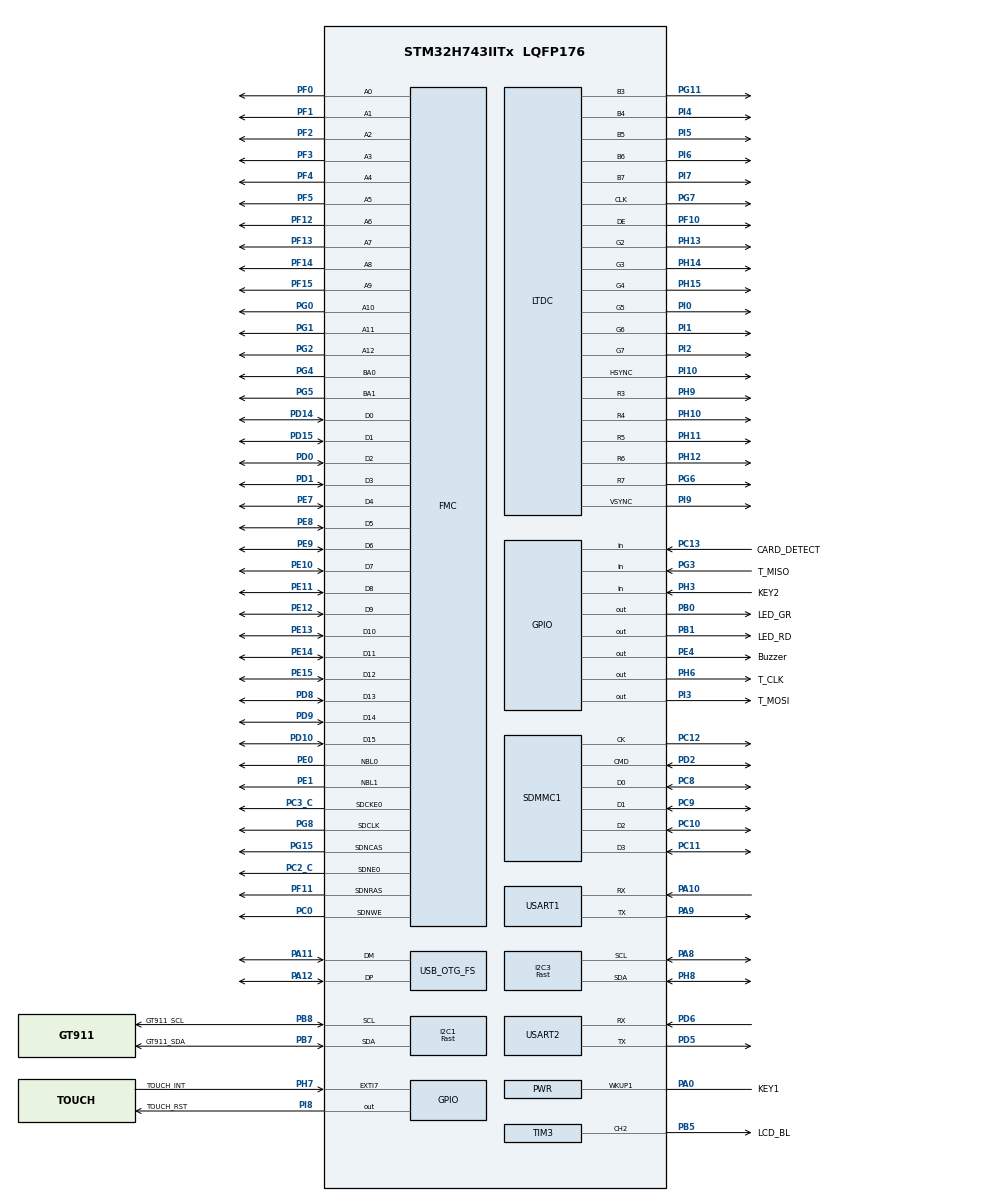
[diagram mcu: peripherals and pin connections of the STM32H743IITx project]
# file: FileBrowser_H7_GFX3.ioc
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ADC3.Channel-0\#ChannelRegularConversion=ADC_CHANNEL_VBAT
ADC3.Channel-1\#ChannelRegularConversion=ADC_CHANNEL_TEMPSENSOR
ADC3.Channel-2\#ChannelRegularConversion=ADC_CHANNEL_VREFINT
ADC3.ClockPrescaler=ADC_CLOCK_ASYNC_DIV6
ADC3.ClockPrescalerADC3=ADC_CLOCK_ASYNC_DIV6
ADC3.ContinuousConvMode=DISABLE
ADC3.ConversionDataManagement=ADC_CONVERSIONDATA_DMA_CIRCULAR
ADC3.EOCSelection=ADC_EOC_SINGLE_CONV
ADC3.ExternalTrigConv=ADC_EXTERNALTRIG_T8_TRGO
ADC3.ExternalTrigConvEdge=ADC_EXTERNALTRIGCONVEDGE_RISING
ADC3.LowPowerAutoWait=DISABLE
ADC3.NbrOfConversion=3
ADC3.NbrOfConversionFlag=1
ADC3.OffsetNumber-0\#ChannelRegularConversion=ADC_OFFSET_NONE
ADC3.OffsetNumber-1\#ChannelRegularConversion=ADC_OFFSET_NONE
ADC3.OffsetNumber-2\#ChannelRegularConversion=ADC_OFFSET_NONE
ADC3.OffsetSignedSaturation-0\#ChannelRegularConversion=DISABLE
ADC3.OffsetSignedSaturation-1\#ChannelRegularConversion=DISABLE
ADC3.OffsetSignedSaturation-2\#ChannelRegularConversion=DISABLE
ADC3.Overrun=ADC_OVR_DATA_PRESERVED
ADC3.OversamplingMode=ENABLE
ADC3.Rank-0\#ChannelRegularConversion=1
ADC3.Rank-1\#ChannelRegularConversion=2
ADC3.Rank-2\#ChannelRegularConversion=3
ADC3.Ratio=1024
ADC3.RightBitShift=ADC_RIGHTBITSHIFT_10
ADC3.SamplingTime-0\#ChannelRegularConversion=ADC_SAMPLETIME_64CYCLES_5
ADC3.SamplingTime-1\#ChannelRegularConversion=ADC_SAMPLETIME_64CYCLES_5
ADC3.SamplingTime-2\#ChannelRegularConversion=ADC_SAMPLETIME_64CYCLES_5
CORTEX_M7.AccessPermission-Cortex_Memory_Protection_Unit_Region0_Settings=MPU_REGION_FULL_ACCESS
CORTEX_M7.AccessPermission-Cortex_Memory_Protection_Unit_Region2_Settings=MPU_REGION_FULL_ACCESS
CORTEX_M7.AccessPermission-Cortex_Memory_Protection_Unit_Region3_Settings=MPU_REGION_FULL_ACCESS
CORTEX_M7.AccessPermission-Cortex_Memory_Protection_Unit_Region4_Settings=MPU_REGION_FULL_ACCESS
CORTEX_M7.AccessPermission-Cortex_Memory_Protection_Unit_Region5_Settings=MPU_REGION_FULL_ACCESS
CORTEX_M7.AccessPermission-Cortex_Memory_Protection_Unit_Region6_Settings=MPU_REGION_FULL_ACCESS
CORTEX_M7.AccessPermission-Cortex_Memory_Protection_Unit_Region7_Settings=MPU_REGION_FULL_ACCESS
CORTEX_M7.BaseAddress-Cortex_Memory_Protection_Unit_Region0_Settings=0x24000000
CORTEX_M7.BaseAddress-Cortex_Memory_Protection_Unit_Region1_Settings=0xC0000000
CORTEX_M7.BaseAddress-Cortex_Memory_Protection_Unit_Region2_Settings=0xC0000000
CORTEX_M7.BaseAddress-Cortex_Memory_Protection_Unit_Region3_Settings=0x90000000
CORTEX_M7.BaseAddress-Cortex_Memory_Protection_Unit_Region4_Settings=0x90000000
CORTEX_M7.BaseAddress-Cortex_Memory_Protection_Unit_Region5_Settings=0x90000000
CORTEX_M7.BaseAddress-Cortex_Memory_Protection_Unit_Region6_Settings=0x30000000
CORTEX_M7.BaseAddress-Cortex_Memory_Protection_Unit_Region7_Settings=0x38000000
CORTEX_M7.CPU_DCache=Enabled
CORTEX_M7.CPU_ICache=Enabled
CORTEX_M7.DisableExec-Cortex_Memory_Protection_Unit_Region0_Settings=MPU_INSTRUCTION_ACCESS_DISABLE
CORTEX_M7.DisableExec-Cortex_Memory_Protection_Unit_Region1_Settings=MPU_INSTRUCTION_ACCESS_DISABLE
CORTEX_M7.DisableExec-Cortex_Memory_Protection_Unit_Region2_Settings=MPU_INSTRUCTION_ACCESS_DISABLE
CORTEX_M7.DisableExec-Cortex_Memory_Protection_Unit_Region3_Settings=MPU_INSTRUCTION_ACCESS_DISABLE
CORTEX_M7.DisableExec-Cortex_Memory_Protection_Unit_Region4_Settings=MPU_INSTRUCTION_ACCESS_ENABLE
CORTEX_M7.DisableExec-Cortex_Memory_Protection_Unit_Region6_Settings=MPU_INSTRUCTION_ACCESS_DISABLE
CORTEX_M7.DisableExec-Cortex_Memory_Protection_Unit_Region7_Settings=MPU_INSTRUCTION_ACCESS_DISABLE
CORTEX_M7.Enable-Cortex_Memory_Protection_Unit_Region0_Settings=MPU_REGION_ENABLE
CORTEX_M7.Enable-Cortex_Memory_Protection_Unit_Region1_Settings=MPU_REGION_ENABLE
CORTEX_M7.Enable-Cortex_Memory_Protection_Unit_Region2_Settings=MPU_REGION_ENABLE
CORTEX_M7.Enable-Cortex_Memory_Protection_Unit_Region3_Settings=MPU_REGION_ENABLE
CORTEX_M7.Enable-Cortex_Memory_Protection_Unit_Region4_Settings=MPU_REGION_ENABLE
CORTEX_M7.Enable-Cortex_Memory_Protection_Unit_Region5_Settings=MPU_REGION_ENABLE
CORTEX_M7.Enable-Cortex_Memory_Protection_Unit_Region6_Settings=MPU_REGION_ENABLE
CORTEX_M7.Enable-Cortex_Memory_Protection_Unit_Region7_Settings=MPU_REGION_ENABLE
CORTEX_M7.Enable-Cortex_Memory_Protection_Unit_Region8_Settings=__NULL
CORTEX_M7.IsBufferable-Cortex_Memory_Protection_Unit_Region0_Settings=MPU_ACCESS_BUFFERABLE
CORTEX_M7.IsBufferable-Cortex_Memory_Protection_Unit_Region2_Settings=MPU_ACCESS_BUFFERABLE
CORTEX_M7.IsBufferable-Cortex_Memory_Protection_Unit_Region3_Settings=MPU_ACCESS_BUFFERABLE
CORTEX_M7.IsBufferable-Cortex_Memory_Protection_Unit_Region4_Settings=MPU_ACCESS_BUFFERABLE
CORTEX_M7.IsBufferable-Cortex_Memory_Protection_Unit_Region5_Settings=MPU_ACCESS_BUFFERABLE
CORTEX_M7.IsCacheable-Cortex_Memory_Protection_Unit_Region0_Settings=MPU_ACCESS_CACHEABLE
CORTEX_M7.IsCacheable-Cortex_Memory_Protection_Unit_Region2_Settings=MPU_ACCESS_CACHEABLE
CORTEX_M7.IsCacheable-Cortex_Memory_Protection_Unit_Region3_Settings=MPU_ACCESS_CACHEABLE
CORTEX_M7.IsCacheable-Cortex_Memory_Protection_Unit_Region4_Settings=MPU_ACCESS_CACHEABLE
CORTEX_M7.IsCacheable-Cortex_Memory_Protection_Unit_Region5_Settings=MPU_ACCESS_CACHEABLE
CORTEX_M7.MPU_Control=MPU_PRIVILEGED_DEFAULT
CORTEX_M7.Size-Cortex_Memory_Protection_Unit_Region0_Settings=MPU_REGION_SIZE_512KB
CORTEX_M7.Size-Cortex_Memory_Protection_Unit_Region1_Settings=MPU_REGION_SIZE_512MB
CORTEX_M7.Size-Cortex_Memory_Protection_Unit_Region2_Settings=MPU_REGION_SIZE_32MB
CORTEX_M7.Size-Cortex_Memory_Protection_Unit_Region3_Settings=MPU_REGION_SIZE_512MB
CORTEX_M7.Size-Cortex_Memory_Protection_Unit_Region4_Settings=MPU_REGION_SIZE_32MB
CORTEX_M7.Size-Cortex_Memory_Protection_Unit_Region5_Settings=MPU_REGION_SIZE_1MB
CORTEX_M7.Size-Cortex_Memory_Protection_Unit_Region6_Settings=MPU_REGION_SIZE_64KB
CORTEX_M7.Size-Cortex_Memory_Protection_Unit_Region7_Settings=MPU_REGION_SIZE_32KB
CORTEX_M7.default_mode_Activation=0
CRC.OutputDataInversionMode=CRC_OUTPUTDATA_INVERSION_DISABLE
DMA2D.ColorMode=DMA2D_OUTPUT_RGB565
DMA2D.Mode=DMA2D_M2M
Dma.ADC3.0.Direction=DMA_PERIPH_TO_MEMORY
Dma.ADC3.0.EventEnable=DISABLE
Dma.ADC3.0.FIFOMode=DMA_FIFOMODE_DISABLE
Dma.ADC3.0.Instance=DMA1_Stream1
Dma.ADC3.0.MemDataAlignment=DMA_MDATAALIGN_HALFWORD
Dma.ADC3.0.MemInc=DMA_MINC_ENABLE
Dma.ADC3.0.Mode=DMA_CIRCULAR
Dma.ADC3.0.PeriphDataAlignment=DMA_PDATAALIGN_HALFWORD
Dma.ADC3.0.PeriphInc=DMA_PINC_DISABLE
Dma.ADC3.0.Polarity=HAL_DMAMUX_REQ_GEN_RISING
Dma.ADC3.0.Priority=DMA_PRIORITY_LOW
Dma.ADC3.0.RequestNumber=1
Dma.ADC3.0.SignalID=NONE
Dma.ADC3.0.SyncEnable=DISABLE
Dma.ADC3.0.SyncPolarity=HAL_DMAMUX_SYNC_NO_EVENT
Dma.ADC3.0.SyncRequestNumber=1
Dma.ADC3.0.SyncSignalID=NONE
Dma.I2C1_RX.2.Direction=DMA_PERIPH_TO_MEMORY
Dma.I2C1_RX.2.EventEnable=DISABLE
Dma.I2C1_RX.2.FIFOMode=DMA_FIFOMODE_DISABLE
Dma.I2C1_RX.2.Instance=DMA1_Stream4
Dma.I2C1_RX.2.MemDataAlignment=DMA_MDATAALIGN_BYTE
Dma.I2C1_RX.2.MemInc=DMA_MINC_ENABLE
Dma.I2C1_RX.2.Mode=DMA_NORMAL
Dma.I2C1_RX.2.PeriphDataAlignment=DMA_PDATAALIGN_BYTE
Dma.I2C1_RX.2.PeriphInc=DMA_PINC_DISABLE
Dma.I2C1_RX.2.Polarity=HAL_DMAMUX_REQ_GEN_RISING
Dma.I2C1_RX.2.Priority=DMA_PRIORITY_VERY_HIGH
Dma.I2C1_RX.2.RequestNumber=1
Dma.I2C1_RX.2.SignalID=NONE
Dma.I2C1_RX.2.SyncEnable=DISABLE
Dma.I2C1_RX.2.SyncPolarity=HAL_DMAMUX_SYNC_NO_EVENT
Dma.I2C1_RX.2.SyncRequestNumber=1
Dma.I2C1_RX.2.SyncSignalID=NONE
Dma.I2C1_TX.3.Direction=DMA_MEMORY_TO_PERIPH
Dma.I2C1_TX.3.EventEnable=DISABLE
Dma.I2C1_TX.3.FIFOMode=DMA_FIFOMODE_DISABLE
Dma.I2C1_TX.3.Instance=DMA1_Stream5
Dma.I2C1_TX.3.MemDataAlignment=DMA_MDATAALIGN_BYTE
Dma.I2C1_TX.3.MemInc=DMA_MINC_ENABLE
Dma.I2C1_TX.3.Mode=DMA_NORMAL
Dma.I2C1_TX.3.PeriphDataAlignment=DMA_PDATAALIGN_BYTE
Dma.I2C1_TX.3.PeriphInc=DMA_PINC_DISABLE
Dma.I2C1_TX.3.Polarity=HAL_DMAMUX_REQ_GEN_RISING
Dma.I2C1_TX.3.Priority=DMA_PRIORITY_VERY_HIGH
Dma.I2C1_TX.3.RequestNumber=1
Dma.I2C1_TX.3.SignalID=NONE
Dma.I2C1_TX.3.SyncEnable=DISABLE
Dma.I2C1_TX.3.SyncPolarity=HAL_DMAMUX_SYNC_NO_EVENT
Dma.I2C1_TX.3.SyncRequestNumber=1
Dma.I2C1_TX.3.SyncSignalID=NONE
Dma.I2C3_RX.5.Direction=DMA_PERIPH_TO_MEMORY
Dma.I2C3_RX.5.EventEnable=DISABLE
Dma.I2C3_RX.5.FIFOMode=DMA_FIFOMODE_DISABLE
Dma.I2C3_RX.5.Instance=DMA1_Stream7
Dma.I2C3_RX.5.MemDataAlignment=DMA_MDATAALIGN_BYTE
Dma.I2C3_RX.5.MemInc=DMA_MINC_ENABLE
Dma.I2C3_RX.5.Mode=DMA_NORMAL
Dma.I2C3_RX.5.PeriphDataAlignment=DMA_PDATAALIGN_BYTE
Dma.I2C3_RX.5.PeriphInc=DMA_PINC_DISABLE
Dma.I2C3_RX.5.Polarity=HAL_DMAMUX_REQ_GEN_RISING
Dma.I2C3_RX.5.Priority=DMA_PRIORITY_HIGH
Dma.I2C3_RX.5.RequestNumber=1
Dma.I2C3_RX.5.SignalID=NONE
Dma.I2C3_RX.5.SyncEnable=DISABLE
Dma.I2C3_RX.5.SyncPolarity=HAL_DMAMUX_SYNC_NO_EVENT
Dma.I2C3_RX.5.SyncRequestNumber=1
Dma.I2C3_RX.5.SyncSignalID=NONE
Dma.I2C3_TX.6.Direction=DMA_MEMORY_TO_PERIPH
Dma.I2C3_TX.6.EventEnable=DISABLE
Dma.I2C3_TX.6.FIFOMode=DMA_FIFOMODE_DISABLE
Dma.I2C3_TX.6.Instance=DMA2_Stream0
Dma.I2C3_TX.6.MemDataAlignment=DMA_MDATAALIGN_BYTE
Dma.I2C3_TX.6.MemInc=DMA_MINC_ENABLE
Dma.I2C3_TX.6.Mode=DMA_NORMAL
Dma.I2C3_TX.6.PeriphDataAlignment=DMA_PDATAALIGN_BYTE
Dma.I2C3_TX.6.PeriphInc=DMA_PINC_DISABLE
Dma.I2C3_TX.6.Polarity=HAL_DMAMUX_REQ_GEN_RISING
Dma.I2C3_TX.6.Priority=DMA_PRIORITY_HIGH
Dma.I2C3_TX.6.RequestNumber=1
Dma.I2C3_TX.6.SignalID=NONE
Dma.I2C3_TX.6.SyncEnable=DISABLE
Dma.I2C3_TX.6.SyncPolarity=HAL_DMAMUX_SYNC_NO_EVENT
Dma.I2C3_TX.6.SyncRequestNumber=1
Dma.I2C3_TX.6.SyncSignalID=NONE
Dma.Request0=ADC3
Dma.Request1=TIM3_CH2
Dma.Request2=I2C1_RX
Dma.Request3=I2C1_TX
Dma.Request4=TIM2_UP
Dma.Request5=I2C3_RX
Dma.Request6=I2C3_TX
Dma.Request7=USART1_RX
Dma.TIM2_UP.4.Direction=DMA_PERIPH_TO_MEMORY
Dma.TIM2_UP.4.EventEnable=DISABLE
Dma.TIM2_UP.4.FIFOMode=DMA_FIFOMODE_DISABLE
Dma.TIM2_UP.4.Instance=DMA1_Stream6
Dma.TIM2_UP.4.MemDataAlignment=DMA_MDATAALIGN_WORD
Dma.TIM2_UP.4.MemInc=DMA_MINC_ENABLE
Dma.TIM2_UP.4.Mode=DMA_CIRCULAR
Dma.TIM2_UP.4.PeriphDataAlignment=DMA_PDATAALIGN_WORD
Dma.TIM2_UP.4.PeriphInc=DMA_PINC_DISABLE
Dma.TIM2_UP.4.Polarity=HAL_DMAMUX_REQ_GEN_RISING
Dma.TIM2_UP.4.Priority=DMA_PRIORITY_LOW
Dma.TIM2_UP.4.RequestNumber=1
Dma.TIM2_UP.4.SignalID=NONE
Dma.TIM2_UP.4.SyncEnable=DISABLE
Dma.TIM2_UP.4.SyncPolarity=HAL_DMAMUX_SYNC_NO_EVENT
Dma.TIM2_UP.4.SyncRequestNumber=1
Dma.TIM2_UP.4.SyncSignalID=NONE
Dma.TIM3_CH2.1.Direction=DMA_MEMORY_TO_PERIPH
Dma.TIM3_CH2.1.EventEnable=DISABLE
Dma.TIM3_CH2.1.FIFOMode=DMA_FIFOMODE_DISABLE
Dma.TIM3_CH2.1.Instance=DMA1_Stream2
Dma.TIM3_CH2.1.MemDataAlignment=DMA_MDATAALIGN_WORD
Dma.TIM3_CH2.1.MemInc=DMA_MINC_ENABLE
Dma.TIM3_CH2.1.Mode=DMA_CIRCULAR
Dma.TIM3_CH2.1.PeriphDataAlignment=DMA_PDATAALIGN_WORD
Dma.TIM3_CH2.1.PeriphInc=DMA_PINC_DISABLE
Dma.TIM3_CH2.1.Polarity=HAL_DMAMUX_REQ_GEN_RISING
Dma.TIM3_CH2.1.Priority=DMA_PRIORITY_HIGH
Dma.TIM3_CH2.1.RequestNumber=1
Dma.TIM3_CH2.1.SignalID=NONE
Dma.TIM3_CH2.1.SyncEnable=DISABLE
Dma.TIM3_CH2.1.SyncPolarity=HAL_DMAMUX_SYNC_NO_EVENT
Dma.TIM3_CH2.1.SyncRequestNumber=1
Dma.TIM3_CH2.1.SyncSignalID=NONE
Dma.USART1_RX.7.Direction=DMA_PERIPH_TO_MEMORY
Dma.USART1_RX.7.EventEnable=DISABLE
Dma.USART1_RX.7.FIFOMode=DMA_FIFOMODE_DISABLE
Dma.USART1_RX.7.Instance=DMA2_Stream1
Dma.USART1_RX.7.MemDataAlignment=DMA_MDATAALIGN_BYTE
Dma.USART1_RX.7.MemInc=DMA_MINC_ENABLE
Dma.USART1_RX.7.Mode=DMA_CIRCULAR
Dma.USART1_RX.7.PeriphDataAlignment=DMA_PDATAALIGN_BYTE
Dma.USART1_RX.7.PeriphInc=DMA_PINC_DISABLE
Dma.USART1_RX.7.Polarity=HAL_DMAMUX_REQ_GEN_RISING
Dma.USART1_RX.7.Priority=DMA_PRIORITY_LOW
Dma.USART1_RX.7.RequestNumber=1
Dma.USART1_RX.7.SignalID=NONE
Dma.USART1_RX.7.SyncEnable=DISABLE
Dma.USART1_RX.7.SyncPolarity=HAL_DMAMUX_SYNC_NO_EVENT
Dma.USART1_RX.7.SyncRequestNumber=1
Dma.USART1_RX.7.SyncSignalID=NONE
FATFS.BSP.number=1
FATFS._FS_NORTC=0
FATFS._FS_RPATH=2
FATFS._FS_TIMEOUT=10000
FATFS._MAX_SS=4096
FATFS._USE_CHMOD=1
FATFS._USE_EXPAND=1
FATFS._USE_FIND=1
FATFS._USE_FORWARD=1
FATFS._USE_LABEL=1
FATFS._USE_LFN=3
FATFS._USE_MUTEX=1
FATFS0.BSP.STBoard=false
FATFS0.BSP.api=Unknown
FATFS0.BSP.instance=PC13
FATFS0.BSP.ip=GPIO
FATFS0.BSP.mode=Input
FATFS0.BSP.name=Detect_SDIO
FATFS0.BSP.solution=PC13
FMC.CASLatency1=FMC_SDRAM_CAS_LATENCY_2
FMC.ColumnBitsNumber1=FMC_SDRAM_COLUMN_BITS_NUM_9
FMC.ExitSelfRefreshDelay1=7
FMC.LoadToActiveDelay1=2
FMC.RCDDelay1=2
FMC.RPDelay1=2
FMC.ReadBurst1=FMC_SDRAM_RBURST_ENABLE
FMC.ReadPipeDelay1=FMC_SDRAM_RPIPE_DELAY_0
FMC.RowCycleDelay1=7
FMC.SDClockPeriod1=FMC_SDRAM_CLOCK_PERIOD_3
FMC.SDClockPeriod2=FMC_SDRAM_CLOCK_PERIOD_3
FMC.SelfRefreshTime1=4
FMC.WriteProtection1=FMC_SDRAM_WRITE_PROTECTION_DISABLE
FMC.WriteRecoveryTime1=3
FREERTOS.INCLUDE_vTaskDelayUntil=1
FREERTOS.INCLUDE_xSemaphoreGetMutexHolder=0
FREERTOS.Mutexes01=touch_mutex,Dynamic,NULL,Depleted;xDataMutex,Dynamic,NULL,Depleted;spi_mutex,Dynamic,NULL,Depleted;xTPMutex,Dynamic,NULL,Depleted
FREERTOS.Tasks01=defaultTask,15,256,StartDefaultTask,Default,NULL,Dynamic,NULL,NULL;TouchGFXTask,25,10000,TouchGFX_Task,As external,NULL,Dynamic,NULL,NULL;brightnessLcdTa,16,512,StartTaskBrightnessLCD,Default,NULL,Dynamic,NULL,NULL;VideoTask,9,4096,videoTaskFunc,As external,NULL,Dynamic,NULL,NULL;uSDTask,14,512,StartTaskuSD,Default,NULL,Dynamic,NULL,NULL;TouchTask,23,256,StartTouchTask,Default,NULL,Dynamic,NULL,NULL;TouchCalibKeyTa,17,256,StartTouchCalibKeyTask,Default,NULL,Dynamic,NULL,NULL
FREERTOS.configCHECK_FOR_STACK_OVERFLOW=2
FREERTOS.configENABLE_FPU=1
FREERTOS.configMINIMAL_STACK_SIZE=256
FREERTOS.configTOTAL_HEAP_SIZE=160000
FREERTOS.configUSE_APPLICATION_TASK_TAG=1
FREERTOS.configUSE_COUNTING_SEMAPHORES=1
FREERTOS.configUSE_IDLE_HOOK=1
FREERTOS.configUSE_MALLOC_FAILED_HOOK=1
FREERTOS.configUSE_NEWLIB_REENTRANT=1
FREERTOS.configUSE_POSIX_ERRNO=0
FREERTOS.configUSE_TICKLESS_IDLE=1
FREERTOS.configUSE_TICK_HOOK=0
FREERTOS.configUSE_TIMERS=0
FREERTOS.copyHeapFile=1
I2C1.DualAddressMode=I2C_DUALADDRESS_DISABLE
I2C1.GeneralCallMode=I2C_GENERALCALL_DISABLE
I2C1.I2C_Speed_Mode=I2C_Fast
I2C1.NoStretchMode=I2C_NOSTRETCH_DISABLE
I2C1.Timing=0x00602173
I2C3.GeneralCallMode=I2C_GENERALCALL_ENABLE
I2C3.I2C_Speed_Mode=I2C_Fast
I2C3.Timing=0x00602173
JPEG.JPEG_RGB_FORMAT=JPEG_RGB565
LIBJPEG.LIBJPEG_FS_type=Stdio
LIBJPEG.RGB_ORDERING=BGR
LPTIM1.ClockPrescaler=LPTIM_PRESCALER_DIV32
LTDC.ActiveH=600
LTDC.ActiveW=1024
LTDC.Alpha0_L0=0
LTDC.Alpha_L0=255
LTDC.BlendingFactor1_L0=LTDC_BLENDING_FACTOR1_CA
LTDC.BlendingFactor2_L0=LTDC_BLENDING_FACTOR2_CA
LTDC.Blue_L0=255
LTDC.FBStartAdress_L0=0
LTDC.HBP=88
LTDC.HFP=40
LTDC.HSync=40
LTDC.ImageHeight_L0=600
LTDC.ImageWidth_L0=1024
LTDC.Layers=0
LTDC.PixelFormat_L0=LTDC_PIXEL_FORMAT_RGB565
LTDC.VBP=20
LTDC.VFP=20
LTDC.VSync=10
LTDC.WindowX1_L0=1024
LTDC.WindowY1_L0=600
Mcu.Family=STM32H7
Mcu.Name=STM32H743IITx
Mcu.Package=LQFP176
Mdma.MDMA_Channel6.JPEG_OUTFIFO_TH.0.BlockCount=0
Mdma.MDMA_Channel6.JPEG_OUTFIFO_TH.0.BlockDataLength=0
Mdma.MDMA_Channel6.JPEG_OUTFIFO_TH.0.BufferTransferLength=32
Mdma.MDMA_Channel6.JPEG_OUTFIFO_TH.0.CircularMode=MDMA_LINEAR_LIST
Mdma.MDMA_Channel6.JPEG_OUTFIFO_TH.0.DataAlignment=MDMA_DATAALIGN_PACKENABLE
Mdma.MDMA_Channel6.JPEG_OUTFIFO_TH.0.DestBlockAddressOffset=0
Mdma.MDMA_Channel6.JPEG_OUTFIFO_TH.0.DestBurst=MDMA_DEST_BURST_32BEATS
Mdma.MDMA_Channel6.JPEG_OUTFIFO_TH.0.DestDataSize=MDMA_DEST_DATASIZE_BYTE
Mdma.MDMA_Channel6.JPEG_OUTFIFO_TH.0.DestinationInc=MDMA_DEST_INC_BYTE
Mdma.MDMA_Channel6.JPEG_OUTFIFO_TH.0.DstAddress=0
Mdma.MDMA_Channel6.JPEG_OUTFIFO_TH.0.Endianness=MDMA_LITTLE_ENDIANNESS_PRESERVE
Mdma.MDMA_Channel6.JPEG_OUTFIFO_TH.0.Instance=MDMA_Channel6
Mdma.MDMA_Channel6.JPEG_OUTFIFO_TH.0.MaskAddress=0
Mdma.MDMA_Channel6.JPEG_OUTFIFO_TH.0.MaskData=0
Mdma.MDMA_Channel6.JPEG_OUTFIFO_TH.0.Priority=MDMA_PRIORITY_VERY_HIGH
Mdma.MDMA_Channel6.JPEG_OUTFIFO_TH.0.Rank=First
Mdma.MDMA_Channel6.JPEG_OUTFIFO_TH.0.SourceBlockAddressOffset=0
Mdma.MDMA_Channel6.JPEG_OUTFIFO_TH.0.SourceBurst=MDMA_SOURCE_BURST_SINGLE
Mdma.MDMA_Channel6.JPEG_OUTFIFO_TH.0.SourceDataSize=MDMA_SRC_DATASIZE_WORD
Mdma.MDMA_Channel6.JPEG_OUTFIFO_TH.0.SourceInc=MDMA_SRC_INC_DISABLE
Mdma.MDMA_Channel6.JPEG_OUTFIFO_TH.0.SrcAddress=0
Mdma.MDMA_Channel6.JPEG_OUTFIFO_TH.0.TransferTriggerMode=MDMA_BUFFER_TRANSFER
Mdma.MDMA_Channel6.Request0=JPEG_OUTFIFO_TH
Mdma.MDMA_Channel6.RequestsNb=1
Mdma.MDMA_Channel7.JPEG_INFIFO_TH.0.BlockCount=0
Mdma.MDMA_Channel7.JPEG_INFIFO_TH.0.BlockDataLength=0
Mdma.MDMA_Channel7.JPEG_INFIFO_TH.0.BufferTransferLength=32
Mdma.MDMA_Channel7.JPEG_INFIFO_TH.0.CircularMode=MDMA_LINEAR_LIST
Mdma.MDMA_Channel7.JPEG_INFIFO_TH.0.DataAlignment=MDMA_DATAALIGN_PACKENABLE
Mdma.MDMA_Channel7.JPEG_INFIFO_TH.0.DestBlockAddressOffset=0
Mdma.MDMA_Channel7.JPEG_INFIFO_TH.0.DestBurst=MDMA_DEST_BURST_32BEATS
Mdma.MDMA_Channel7.JPEG_INFIFO_TH.0.DestDataSize=MDMA_DEST_DATASIZE_WORD
Mdma.MDMA_Channel7.JPEG_INFIFO_TH.0.DestinationInc=MDMA_DEST_INC_DISABLE
Mdma.MDMA_Channel7.JPEG_INFIFO_TH.0.DstAddress=0
Mdma.MDMA_Channel7.JPEG_INFIFO_TH.0.Endianness=MDMA_LITTLE_ENDIANNESS_PRESERVE
Mdma.MDMA_Channel7.JPEG_INFIFO_TH.0.Instance=MDMA_Channel7
Mdma.MDMA_Channel7.JPEG_INFIFO_TH.0.MaskAddress=0
Mdma.MDMA_Channel7.JPEG_INFIFO_TH.0.MaskData=0
Mdma.MDMA_Channel7.JPEG_INFIFO_TH.0.Priority=MDMA_PRIORITY_VERY_HIGH
Mdma.MDMA_Channel7.JPEG_INFIFO_TH.0.Rank=First
Mdma.MDMA_Channel7.JPEG_INFIFO_TH.0.SourceBlockAddressOffset=0
Mdma.MDMA_Channel7.JPEG_INFIFO_TH.0.SourceBurst=MDMA_SOURCE_BURST_32BEATS
Mdma.MDMA_Channel7.JPEG_INFIFO_TH.0.SourceDataSize=MDMA_SRC_DATASIZE_BYTE
Mdma.MDMA_Channel7.JPEG_INFIFO_TH.0.SourceInc=MDMA_SRC_INC_BYTE
Mdma.MDMA_Channel7.JPEG_INFIFO_TH.0.SrcAddress=0
Mdma.MDMA_Channel7.JPEG_INFIFO_TH.0.TransferTriggerMode=MDMA_BUFFER_TRANSFER
Mdma.MDMA_Channel7.Request0=JPEG_INFIFO_TH
Mdma.MDMA_Channel7.RequestsNb=1
Mdma.RequestSet0=MDMA_Channel7
Mdma.RequestSet1=MDMA_Channel6
Mdma.RequestSetsNb=2
NVIC.ADC3_IRQn=true\:5\:0\:false\:false\:true\:true\:true\:true\:true
NVIC.DMA1_Stream1_IRQn=true\:5\:0\:false\:false\:true\:true\:false\:true\:true
NVIC.DMA1_Stream2_IRQn=true\:5\:0\:false\:false\:true\:false\:false\:true\:true
NVIC.DMA1_Stream4_IRQn=true\:5\:0\:false\:false\:true\:true\:false\:true\:true
NVIC.DMA1_Stream5_IRQn=true\:5\:0\:false\:false\:true\:true\:false\:true\:true
NVIC.DMA1_Stream6_IRQn=true\:5\:0\:false\:false\:true\:true\:false\:true\:true
NVIC.DMA1_Stream7_IRQn=true\:5\:0\:false\:false\:true\:true\:false\:true\:true
NVIC.DMA2D_IRQn=true\:5\:0\:false\:false\:true\:false\:true\:true\:true
NVIC.DMA2_Stream0_IRQn=true\:5\:0\:false\:false\:true\:true\:false\:true\:true
NVIC.DMA2_Stream1_IRQn=true\:5\:0\:false\:false\:true\:true\:false\:true\:true
NVIC.EXTI9_5_IRQn=true\:5\:0\:false\:false\:true\:true\:true\:true\:true
NVIC.I2C1_ER_IRQn=true\:5\:0\:false\:false\:true\:true\:true\:true\:true
NVIC.JPEG_IRQn=true\:5\:0\:false\:false\:true\:true\:true\:true\:true
NVIC.LPTIM1_IRQn=true\:5\:0\:false\:false\:true\:true\:true\:true\:true
NVIC.LTDC_IRQn=true\:5\:0\:false\:false\:true\:true\:true\:true\:true
NVIC.MDMA_IRQn=true\:5\:0\:false\:false\:true\:true\:false\:true\:true
NVIC.OTG_FS_IRQn=true\:5\:0\:false\:false\:true\:true\:false\:true\:true
NVIC.PriorityGroup=NVIC_PRIORITYGROUP_4
NVIC.RCC_IRQn=true\:5\:0\:false\:false\:true\:true\:false\:false\:true
NVIC.SDMMC1_IRQn=true\:5\:0\:false\:false\:true\:true\:true\:true\:true
NVIC.TIM6_DAC_IRQn=true\:15\:0\:false\:false\:true\:false\:false\:true\:true
NVIC.TimeBase=TIM6_DAC_IRQn
NVIC.TimeBaseIP=TIM6
NVIC.USART1_IRQn=true\:5\:0\:false\:false\:true\:true\:true\:true\:true
NVIC.USART2_IRQn=true\:5\:0\:false\:false\:true\:true\:true\:true\:true
NVIC.WAKEUP_PIN_IRQn=true\:5\:0\:false\:false\:true\:true\:true\:true\:true
PA0.GPIO_Label=KEY1
PA0.Mode=WakeUp1
PA0.Signal=PWR_WKUP1
PA10.Mode=Asynchronous
PA10.Signal=USART1_RX
PA11.GPIO_PuPd=GPIO_PULLUP
PA11.GPIO_Speed=GPIO_SPEED_FREQ_VERY_HIGH
PA11.Mode=Device_Only
PA11.Signal=USB_OTG_FS_DM
PA12.GPIO_PuPd=GPIO_PULLUP
PA12.GPIO_Speed=GPIO_SPEED_FREQ_VERY_HIGH
PA12.Mode=Device_Only
PA12.Signal=USB_OTG_FS_DP
PA13\ (JTMS/SWDIO).Mode=Serial_Wire
PA13\ (JTMS/SWDIO).Signal=DEBUG_JTMS-SWDIO
PA14\ (JTCK/SWCLK).Mode=Serial_Wire
PA14\ (JTCK/SWCLK).Signal=DEBUG_JTCK-SWCLK
PA8.GPIO_Pu=GPIO_PULLUP
PA8.GPIO_Speed=GPIO_SPEED_FREQ_VERY_HIGH
PA8.Mode=I2C
PA8.Signal=I2C3_SCL
PA9.Mode=Asynchronous
PA9.Signal=USART1_TX
PB0.GPIO_Label=LED_GR
PB0.PinAttribute=Free
PB0.Signal=GPIO_Output
PB1.GPIO_Label=LED_RD
PB1.PinAttribute=Free
PB1.Signal=GPIO_Output
PB2.GPIO_Speed=GPIO_SPEED_FREQ_VERY_HIGH
PB2.PinAttribute=Free
PB2.Signal=QUADSPI_CLK
PB5.GPIO_Label=LCD_BL
PB5.GPIO_Speed=GPIO_SPEED_FREQ_VERY_HIGH
PB5.Signal=S_TIM3_CH2
PB6.GPIO_Speed=GPIO_SPEED_FREQ_VERY_HIGH
PB6.Signal=QUADSPI_BK1_NCS
PB7.GPIO_Label=GT911_SDA
PB7.GPIO_Pu=GPIO_PULLUP
PB7.GPIO_Speed=GPIO_SPEED_FREQ_VERY_HIGH
PB7.Mode=I2C
PB7.Signal=I2C1_SDA
PB8.GPIO_Label=GT911_SCL
PB8.GPIO_Pu=GPIO_PULLUP
PB8.GPIO_Speed=GPIO_SPEED_FREQ_VERY_HIGH
PB8.Mode=I2C
PB8.Signal=I2C1_SCL
PC0.GPIO_PuPd=GPIO_NOPULL
PC0.Signal=FMC_SDNWE
PC10.Mode=SD_4_bits_Wide_bus
PC10.Signal=SDMMC1_D2
PC11.Mode=SD_4_bits_Wide_bus
PC11.Signal=SDMMC1_D3
PC12.Mode=SD_4_bits_Wide_bus
PC12.Signal=SDMMC1_CK
PC13.GPIO_Label=CARD_DETECT
PC13.GPIO_PuPd=GPIO_PULLUP
PC13.Signal=GPIO_Input
PC14-OSC32_IN\ (OSC32_IN).Mode=LSE-External-Oscillator
PC14-OSC32_IN\ (OSC32_IN).Signal=RCC_OSC32_IN
PC15-OSC32_OUT\ (OSC32_OUT).Mode=LSE-External-Oscillator
PC15-OSC32_OUT\ (OSC32_OUT).Signal=RCC_OSC32_OUT
PC2_C.GPIO_PuPd=GPIO_NOPULL
PC2_C.GPIO_Speed_High_Default=GPIO_SPEED_FREQ_VERY_HIGH
PC2_C.Mode=SdramChipSelect1_1
PC2_C.Signal=FMC_SDNE0
PC3_C.GPIO_PuPd=GPIO_NOPULL
PC3_C.Mode=SdramChipSelect1_1
PC3_C.Signal=FMC_SDCKE0
PC8.Mode=SD_4_bits_Wide_bus
PC8.Signal=SDMMC1_D0
PC9.Mode=SD_4_bits_Wide_bus
PC9.Signal=SDMMC1_D1
PD0.Signal=FMC_D2_DA2
PD1.Signal=FMC_D3_DA3
PD10.Signal=FMC_D15_DA15
PD14.Signal=FMC_D0_DA0
PD15.Signal=FMC_D1_DA1
PD2.Mode=SD_4_bits_Wide_bus
PD2.Signal=SDMMC1_CMD
PD5.GPIO_ModeDefaultPP=GPIO_MODE_AF_PP
PD5.GPIO_PuPd=GPIO_PULLUP
PD5.GPIO_Speed=GPIO_SPEED_FREQ_VERY_HIGH
PD5.Mode=Asynchronous
PD5.Signal=USART2_TX
PD6.GPIO_ModeDefaultPP=GPIO_MODE_AF_PP
PD6.GPIO_PuPd=GPIO_PULLUP
PD6.GPIO_Speed=GPIO_SPEED_FREQ_VERY_HIGH
PD6.Mode=Asynchronous
PD6.Signal=USART2_RX
PD8.Signal=FMC_D13_DA13
PD9.Signal=FMC_D14_DA14
PE0.Signal=FMC_NBL0
PE1.Signal=FMC_NBL1
PE10.Signal=FMC_D7_DA7
PE11.Signal=FMC_D8_DA8
PE12.Signal=FMC_D9_DA9
PE13.Signal=FMC_D10_DA10
PE14.Signal=FMC_D11_DA11
PE15.Signal=FMC_D12_DA12
PE4.GPIO_Label=Buzzer
PE4.GPIO_Speed=GPIO_SPEED_FREQ_LOW
PE4.Signal=GPIO_Output
PE7.Signal=FMC_D4_DA4
PE8.Signal=FMC_D5_DA5
PE9.Signal=FMC_D6_DA6
PF0.Signal=FMC_A0
PF1.Signal=FMC_A1
PF10.GPIO_Speed=GPIO_SPEED_FREQ_VERY_HIGH
PF10.Mode=RGB565
PF10.Signal=LTDC_DE
PF11.PinAttribute=Free
PF11.Signal=FMC_SDNRAS
PF12.PinAttribute=Free
PF12.Signal=FMC_A6
PF13.Signal=FMC_A7
PF14.Signal=FMC_A8
PF15.Signal=FMC_A9
PF2.Signal=FMC_A2
PF3.Signal=FMC_A3
PF4.Signal=FMC_A4
PF5.Signal=FMC_A5
PF6.GPIO_Speed=GPIO_SPEED_FREQ_VERY_HIGH
PF6.Signal=QUADSPI_BK1_IO3
PF7.GPIO_Speed=GPIO_SPEED_FREQ_VERY_HIGH
PF7.Signal=QUADSPI_BK1_IO2
PF8.GPIO_Speed=GPIO_SPEED_FREQ_VERY_HIGH
PF8.Signal=QUADSPI_BK1_IO0
PF9.GPIO_Speed=GPIO_SPEED_FREQ_VERY_HIGH
PF9.Signal=QUADSPI_BK1_IO1
PG0.Signal=FMC_A10
PG1.Signal=FMC_A11
PG11.GPIO_Speed=GPIO_SPEED_FREQ_VERY_HIGH
PG11.Mode=RGB565
PG11.Signal=LTDC_B3
PG15.Signal=FMC_SDNCAS
PG2.Signal=FMC_A12
PG3.GPIO_Label=T_MISO
PG3.GPIO_PuPd=GPIO_NOPULL
PG3.Signal=GPIO_Input
PG4.Signal=FMC_A14_BA0
PG5.Signal=FMC_A15_BA1
PG6.GPIO_Speed=GPIO_SPEED_FREQ_VERY_HIGH
PG6.Mode=RGB565
PG6.Signal=LTDC_R7
PG7.GPIO_Speed=GPIO_SPEED_FREQ_VERY_HIGH
PG7.Mode=RGB565
PG7.Signal=LTDC_CLK
PG8.Signal=FMC_SDCLK
PH0-OSC_IN\ (PH0).Mode=HSE-External-Oscillator
PH0-OSC_IN\ (PH0).Signal=RCC_OSC_IN
PH1-OSC_OUT\ (PH1).Mode=HSE-External-Oscillator
PH1-OSC_OUT\ (PH1).Signal=RCC_OSC_OUT
PH10.GPIO_Speed=GPIO_SPEED_FREQ_VERY_HIGH
PH10.Mode=RGB565
PH10.Signal=LTDC_R4
PH11.GPIO_Speed=GPIO_SPEED_FREQ_VERY_HIGH
PH11.Mode=RGB565
PH11.Signal=LTDC_R5
PH12.GPIO_Speed=GPIO_SPEED_FREQ_VERY_HIGH
PH12.Mode=RGB565
PH12.Signal=LTDC_R6
PH13.GPIO_Speed=GPIO_SPEED_FREQ_VERY_HIGH
PH13.Mode=RGB565
PH13.Signal=LTDC_G2
PH14.GPIO_Speed=GPIO_SPEED_FREQ_VERY_HIGH
PH14.Mode=RGB565
PH14.Signal=LTDC_G3
PH15.GPIO_Speed=GPIO_SPEED_FREQ_VERY_HIGH
PH15.Mode=RGB565
PH15.Signal=LTDC_G4
PH3.GPIO_Label=KEY2
PH3.GPIO_PuPd=GPIO_PULLUP
PH3.PinAttribute=Free
PH3.Signal=GPIO_Input
PH6.GPIO_Label=T_CLK
PH6.GPIO_Speed=GPIO_SPEED_FREQ_VERY_HIGH
PH6.Signal=GPIO_Output
PH7.GPIO_Label=TOUCH_INT
PH7.GPIO_PuPd=GPIO_PULLUP
PH7.Signal=GPXTI7
PH8.GPIO_Pu=GPIO_PULLUP
PH8.GPIO_Speed=GPIO_SPEED_FREQ_VERY_HIGH
PH8.Mode=I2C
PH8.Signal=I2C3_SDA
PH9.GPIO_Speed=GPIO_SPEED_FREQ_VERY_HIGH
PH9.Mode=RGB565
PH9.Signal=LTDC_R3
PI0.GPIO_Speed=GPIO_SPEED_FREQ_VERY_HIGH
PI0.Mode=RGB565
PI0.Signal=LTDC_G5
PI1.GPIO_Speed=GPIO_SPEED_FREQ_VERY_HIGH
PI1.Mode=RGB565
PI1.Signal=LTDC_G6
PI10.GPIO_Speed=GPIO_SPEED_FREQ_VERY_HIGH
PI10.Mode=RGB565
PI10.Signal=LTDC_HSYNC
PI2.GPIO_Speed=GPIO_SPEED_FREQ_VERY_HIGH
PI2.Mode=RGB565
PI2.Signal=LTDC_G7
PI3.GPIO_Label=T_MOSI
PI3.GPIO_PuPd=GPIO_NOPULL
PI3.GPIO_Speed=GPIO_SPEED_FREQ_VERY_HIGH
PI3.Signal=GPIO_Output
PI4.GPIO_Speed=GPIO_SPEED_FREQ_VERY_HIGH
PI4.Mode=RGB565
PI4.Signal=LTDC_B4
PI5.GPIO_Speed=GPIO_SPEED_FREQ_VERY_HIGH
PI5.Mode=RGB565
PI5.Signal=LTDC_B5
PI6.GPIO_Speed=GPIO_SPEED_FREQ_VERY_HIGH
PI6.Mode=RGB565
PI6.PinAttribute=Free
PI6.Signal=LTDC_B6
PI7.GPIO_Speed=GPIO_SPEED_FREQ_VERY_HIGH
PI7.Mode=RGB565
PI7.PinAttribute=Free
PI7.Signal=LTDC_B7
PI8.GPIO_Label=TOUCH_RST
PI8.GPIO_ModeDefaultOutputPP=GPIO_MODE_OUTPUT_PP
PI8.GPIO_PuPd=GPIO_PULLUP
PI8.PinState=GPIO_PIN_RESET
PI8.Signal=GPIO_Output
PI9.GPIO_Speed=GPIO_SPEED_FREQ_VERY_HIGH
PI9.Mode=RGB565
PI9.Signal=LTDC_VSYNC
ProjectManager.HeapSize=0x2000
ProjectManager.StackSize=0x4000
ProjectManager.TargetToolchain=STM32CubeIDE
RCC.ADCCLockSelection=RCC_ADCCLKSOURCE_CLKP
RCC.ADCFreq_Value=64000000
RCC.APB1Freq_Value=120000000
RCC.APB2Freq_Value=120000000
RCC.APB3Freq_Value=120000000
RCC.APB4Freq_Value=120000000
RCC.CortexFreq_Value=480000000
RCC.D1PPRE=RCC_APB3_DIV2
RCC.D2PPRE1=RCC_APB1_DIV2
RCC.D2PPRE2=RCC_APB2_DIV2
RCC.D3PPRE=RCC_APB4_DIV2
RCC.DIVM1=5
RCC.DIVM2=25
RCC.DIVM3=1
RCC.DIVN1=192
RCC.DIVN2=336
RCC.DIVN3=12
RCC.DIVP2=4
RCC.DIVQ1=8
RCC.DIVQ3=10
RCC.DIVR1=4
RCC.DIVR3=10
RCC.HCLKFreq_Value=240000000
RCC.HPRE=RCC_HCLK_DIV2
RCC.I2C123CLockSelection=RCC_I2C123CLKSOURCE_HSI
RCC.LPTIM1CLockSelection=RCC_LPTIM1CLKSOURCE_LSE
RCC.LSE_Drive_Capability=RCC_LSEDRIVE_HIGH
RCC.PLL1_VCI_Range-AdvancedSettings=RCC_PLL1VCIRANGE_0
RCC.PLL2FRACN=0
RCC.PLL2_VCI_Range-AdvancedSettings=RCC_PLL2VCIRANGE_0
RCC.PLL2_VCO_SEL-AdvancedSettings=RCC_PLL2VCOMEDIUM
RCC.PLL3FRACN=0
RCC.PLL3_VCI_Range-AdvancedSettings=RCC_PLL3VCIRANGE_0
RCC.PLL3_VCO_SEL=RCC_PLL3VCOMEDIUM
RCC.PLL3_VCO_SEL-AdvancedSettings=RCC_PLL3VCOMEDIUM
RCC.PLLFRACN=0
RCC.PLLSourceVirtual=RCC_PLLSOURCE_HSE
RCC.PWR_Regulator_Voltage_Scale=PWR_REGULATOR_VOLTAGE_SCALE0
RCC.ProductRev=revV
RCC.RCC_TIM_PRescaler_Selection=RCC_TIMPRES_DESACTIVATED
RCC.RTCClockSelection=RCC_RTCCLKSOURCE_LSE
RCC.SYSCLKFreq_VALUE=480000000
RCC.SYSCLKSource=RCC_SYSCLKSOURCE_PLLCLK
RCC.USART16CLockSelection=RCC_USART16CLKSOURCE_HSI
RCC.USART234578CLockSelection=RCC_USART234578CLKSOURCE_HSI
RCC.USBCLockSelection=RCC_USBCLKSOURCE_HSI48
RCC.USBFreq_Value=48000000
RTC.Year=20
SDMMC1.ClockDiv=8
SH.FMC_A0.0=FMC_A0,13b-sda1
SH.FMC_A1.0=FMC_A1,13b-sda1
SH.FMC_A10.0=FMC_A10,13b-sda1
SH.FMC_A11.0=FMC_A11,13b-sda1
SH.FMC_A12.0=FMC_A12,13b-sda1
SH.FMC_A14_BA0.0=FMC_BA0,FourSdramBanks1
SH.FMC_A15_BA1.0=FMC_BA1,FourSdramBanks1
SH.FMC_A2.0=FMC_A2,13b-sda1
SH.FMC_A3.0=FMC_A3,13b-sda1
SH.FMC_A4.0=FMC_A4,13b-sda1
SH.FMC_A5.0=FMC_A5,13b-sda1
SH.FMC_A6.0=FMC_A6,13b-sda1
SH.FMC_A7.0=FMC_A7,13b-sda1
SH.FMC_A8.0=FMC_A8,13b-sda1
SH.FMC_A9.0=FMC_A9,13b-sda1
SH.FMC_D0_DA0.0=FMC_D0,sd-16b-d1
SH.FMC_D10_DA10.0=FMC_D10,sd-16b-d1
SH.FMC_D11_DA11.0=FMC_D11,sd-16b-d1
SH.FMC_D12_DA12.0=FMC_D12,sd-16b-d1
SH.FMC_D13_DA13.0=FMC_D13,sd-16b-d1
SH.FMC_D14_DA14.0=FMC_D14,sd-16b-d1
SH.FMC_D15_DA15.0=FMC_D15,sd-16b-d1
SH.FMC_D1_DA1.0=FMC_D1,sd-16b-d1
SH.FMC_D2_DA2.0=FMC_D2,sd-16b-d1
SH.FMC_D3_DA3.0=FMC_D3,sd-16b-d1
SH.FMC_D4_DA4.0=FMC_D4,sd-16b-d1
SH.FMC_D5_DA5.0=FMC_D5,sd-16b-d1
SH.FMC_D6_DA6.0=FMC_D6,sd-16b-d1
SH.FMC_D7_DA7.0=FMC_D7,sd-16b-d1
SH.FMC_D8_DA8.0=FMC_D8,sd-16b-d1
SH.FMC_D9_DA9.0=FMC_D9,sd-16b-d1
SH.FMC_NBL0.0=FMC_NBL0,Sd2ByteEnable1
SH.FMC_NBL1.0=FMC_NBL1,Sd2ByteEnable1
SH.FMC_SDCLK.0=FMC_SDCLK,13b-sda1
SH.FMC_SDNCAS.0=FMC_SDNCAS,13b-sda1
SH.FMC_SDNRAS.0=FMC_SDNRAS,13b-sda1
SH.FMC_SDNWE.0=FMC_SDNWE,13b-sda1
SH.S_TIM3_CH2.0=TIM3_CH2,PWM Generation2 CH2
STMicroelectronics.X-CUBE-ALGOBUILD.1.4.0.LibraryCcDSPOoLibraryJjDSPOoLibrary=true
STMicroelectronics.X-CUBE-ALGOBUILD.1.4.0.LibraryCcMotionOoLibrariesJjMotionOoLibraries=true
STMicroelectronics.X-CUBE-TOUCHGFX.4.25.0.ApplicationCcGraphicsJjApplication=TouchGFXOoGenerator
STMicroelectronics.X-CUBE-TOUCHGFX.4.25.0.tgfx_address1=0xC0000000
STMicroelectronics.X-CUBE-TOUCHGFX.4.25.0.tgfx_address2=0xC12C0000
STMicroelectronics.X-CUBE-TOUCHGFX.4.25.0.tgfx_buffering_strategy=Double
STMicroelectronics.X-CUBE-TOUCHGFX.4.25.0.tgfx_display_interface=disp_ltdc
STMicroelectronics.X-CUBE-TOUCHGFX.4.25.0.tgfx_framebuffer_stride=Enabled
STMicroelectronics.X-CUBE-TOUCHGFX.4.25.0.tgfx_hardware_accelerator=dma_2d
STMicroelectronics.X-CUBE-TOUCHGFX.4.25.0.tgfx_location=By Address
STMicroelectronics.X-CUBE-TOUCHGFX.4.25.0.tgfx_nema_cl_size=8192
STMicroelectronics.X-CUBE-TOUCHGFX.4.25.0.tgfx_vector_fonts=Enabled
STMicroelectronics.X-CUBE-TOUCHGFX.4.25.0.tgfx_vector_rendering=Software
STMicroelectronics.X-CUBE-TOUCHGFX.4.25.0.tgfx_video=Hardware
STMicroelectronics.X-CUBE-TOUCHGFX.4.25.0.tgfx_video_height=480
STMicroelectronics.X-CUBE-TOUCHGFX.4.25.0.tgfx_video_strategy=2
STMicroelectronics.X-CUBE-TOUCHGFX.4.25.0.tgfx_video_width=800
STMicroelectronics.X-CUBE-TOUCHGFX.4.25.0.tgfx_vsync=vsync_ltdc
STMicroelectronics.X-CUBE-TOUCHGFX.4.25.0_IsPackSelfContextualization=true
TIM2.Period=0xffffffff-1
TIM2.Prescaler=240-1
TIM3.AutoReloadPreload=TIM_AUTORELOAD_PRELOAD_ENABLE
TIM3.Channel-PWM\ Generation2\ CH2=TIM_CHANNEL_2
TIM3.ClockDivision=TIM_CLOCKDIVISION_DIV1
TIM3.OCFastMode_PWM-PWM\ Generation2\ CH2=TIM_OCFAST_DISABLE
TIM3.OCMode_PWM-PWM\ Generation2\ CH2=TIM_OCMODE_PWM1
TIM3.Period=255
TIM3.Prescaler=0
TIM8.AutoReloadPreload=TIM_AUTORELOAD_PRELOAD_DISABLE
TIM8.Period=1000-1
TIM8.Prescaler=24000-1
TIM8.TIM_MasterOutputTrigger=TIM_TRGO_UPDATE
USART1.OverSampling=UART_OVERSAMPLING_8
USART1.VirtualMode-Asynchronous=VM_ASYNC
USART2.OverSampling=UART_OVERSAMPLING_8
USART2.VirtualMode-Asynchronous=VM_ASYNC
USB_DEVICE.CLASS_NAME_FS=MSC
USB_DEVICE.VirtualMode-MSC_FS=Msc
USB_DEVICE.VirtualModeFS=Msc_FS
USB_OTG_FS.VirtualMode=Device_Only
VP_ADC3_TempSens_Input.Mode=IN-TempSens
VP_ADC3_Vbat_Input.Mode=IN-Vbat
VP_ADC3_Vref_Input.Mode=IN-Vrefint
VP_CRC_VS_CRC.Mode=CRC_Activate
VP_DMA2D_VS_DMA2D.Mode=DMA2D_Activate
VP_FATFS_VS_SDIO.Mode=SDIO
VP_FREERTOS_VS_CMSIS_V2.Mode=CMSIS_V2
VP_JPEG_VS_JPEG.Mode=JPEG_Activate
VP_LIBJPEG_VS_JPEGLIB.Mode=Enabled
VP_LPTIM1_VS_LPTIM_counterModeInternalClock.Mode=Counts__internal_clock_event_00
VP_MEMORYMAP_VS_MEMORYMAP.Mode=CurAppReg
VP_RNG_VS_RNG.Mode=RNG_Activate
VP_RTC_VS_RTC_Activate.Mode=RTC_Enabled
VP_RTC_VS_RTC_Calendar.Mode=RTC_Calendar
VP_STMicroelectronics.X-CUBE-ALGOBUILD_VS_DSPOoLibraryJjLibrary_1.4.0_1.4.0.Mode=DSPOoLibraryJjLibrary
VP_STMicroelectronics.X-CUBE-ALGOBUILD_VS_MotionOoLibrariesJjLibrary_1.4.0_1.4.0.Mode=MotionOoLibrariesJjLibrary
VP_STMicroelectronics.X-CUBE-TOUCHGFX_VS_GraphicsJjApplication_4.25.0.Mode=GraphicsJjApplication
VP_SYS_VS_tim6.Mode=TIM6
VP_TIM2_VS_ClockSourceINT.Mode=Internal
VP_TIM3_VS_ClockSourceINT.Mode=Internal
VP_TIM8_VS_ClockSourceINT.Mode=Internal
VP_USB_DEVICE_VS_USB_DEVICE_MSC_FS.Mode=MSC_FS
board=custom

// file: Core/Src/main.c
/* USER CODE BEGIN Header */
/**
  ******************************************************************************
  * @file           : main.c
  * @brief          : Main program body
  ******************************************************************************
  * @attention
  *
  * Copyright (c) 2022 STMicroelectronics.
  * All rights reserved.
  *
  * This software is licensed under terms that can be found in the LICENSE file
  * in the root directory of this software component.
  * If no LICENSE file comes with this software, it is provided AS-IS.
  *
  ******************************************************************************
  */
/* USER CODE END Header */
#include "main.h"
#include "cmsis_os.h"
#include "fatfs.h"
#include "libjpeg.h"
#include "app_touchgfx.h"
#include "usb_device.h"

/* USER CODE BEGIN Includes */
#include "file_browser.h"
#include <inttypes.h>
/* USER CODE END Includes */

/* USER CODE BEGIN PTD */
buzzer_t Buz;
/* USER CODE END PTD */

/* USER CODE BEGIN PD */
//#define RX_BUFFER_SIZE 			256

//#define REFRESH_COUNT                            ((uint32_t)918)       /*SDRAM refresh counter (120MHz SDRAM clock)*/
//#define SDRAM_TIMEOUT                            ((uint32_t)0xFFFF)
//#define SDRAM_MODEREG_BURST_LENGTH_1             ((uint16_t)0x0000)
//#define SDRAM_MODEREG_BURST_LENGTH_2             ((uint16_t)0x0001)
//#define SDRAM_MODEREG_BURST_LENGTH_4             ((uint16_t)0x0002)
//#define SDRAM_MODEREG_BURST_LENGTH_8             ((uint16_t)0x0004)
//#define SDRAM_MODEREG_BURST_TYPE_SEQUENTIAL      ((uint16_t)0x0000)
//#define SDRAM_MODEREG_BURST_TYPE_INTERLEAVED     ((uint16_t)0x0008)
//#define SDRAM_MODEREG_CAS_LATENCY_2              ((uint16_t)0x0020)
//#define SDRAM_MODEREG_CAS_LATENCY_3              ((uint16_t)0x0030)
//#define SDRAM_MODEREG_OPERATING_MODE_STANDARD    ((uint16_t)0x0000)
//#define SDRAM_MODEREG_WRITEBURST_MODE_PROGRAMMED ((uint16_t)0x0000)
//#define SDRAM_MODEREG_WRITEBURST_MODE_SINGLE     ((uint16_t)0x0200)
/* USER CODE END PD */

/* USER CODE BEGIN PM */
RTC_TimeTypeDef sTime;
RTC_DateTypeDef sDate;
/* USER CODE END PM */

ADC_HandleTypeDef hadc3;
DMA_HandleTypeDef hdma_adc3;

CRC_HandleTypeDef hcrc;

DMA2D_HandleTypeDef hdma2d;

I2C_HandleTypeDef hi2c1;
I2C_HandleTypeDef hi2c3;
DMA_HandleTypeDef hdma_i2c1_rx;
DMA_HandleTypeDef hdma_i2c1_tx;
DMA_HandleTypeDef hdma_i2c3_rx;
DMA_HandleTypeDef hdma_i2c3_tx;

JPEG_HandleTypeDef hjpeg;
MDMA_HandleTypeDef hmdma_jpeg_infifo_th;
MDMA_HandleTypeDef hmdma_jpeg_outfifo_th;

LPTIM_HandleTypeDef hlptim1;

LTDC_HandleTypeDef hltdc;

RNG_HandleTypeDef hrng;

RTC_HandleTypeDef hrtc;

SD_HandleTypeDef hsd1;

TIM_HandleTypeDef htim2;
TIM_HandleTypeDef htim3;
TIM_HandleTypeDef htim8;
DMA_HandleTypeDef hdma_tim2_up;
DMA_HandleTypeDef hdma_tim3_ch2;

UART_HandleTypeDef huart1;
UART_HandleTypeDef huart2;
DMA_HandleTypeDef hdma_usart1_rx;

SDRAM_HandleTypeDef hsdram1;

/* Definitions for defaultTask */
osThreadId_t defaultTaskHandle;
const osThreadAttr_t defaultTask_attributes = {
  .name = "defaultTask",
  .stack_size = 256 * 4,
  .priority = (osPriority_t) osPriorityLow7,
};
/* Definitions for TouchGFXTask */
osThreadId_t TouchGFXTaskHandle;
const osThreadAttr_t TouchGFXTask_attributes = {
  .name = "TouchGFXTask",
  .stack_size = 10000 * 4,
  .priority = (osPriority_t) osPriorityNormal1,
};
/* Definitions for brightnessLcdTa */
osThreadId_t brightnessLcdTaHandle;
const osThreadAttr_t brightnessLcdTa_attributes = {
  .name = "brightnessLcdTa",
  .stack_size = 512 * 4,
  .priority = (osPriority_t) osPriorityBelowNormal,
};
/* Definitions for VideoTask */
osThreadId_t VideoTaskHandle;
const osThreadAttr_t VideoTask_attributes = {
  .name = "VideoTask",
  .stack_size = 4096 * 4,
  .priority = (osPriority_t) osPriorityLow1,
};
/* Definitions for uSDTask */
osThreadId_t uSDTaskHandle;
const osThreadAttr_t uSDTask_attributes = {
  .name = "uSDTask",
  .stack_size = 512 * 4,
  .priority = (osPriority_t) osPriorityLow6,
};
/* Definitions for TouchTask */
osThreadId_t TouchTaskHandle;
const osThreadAttr_t TouchTask_attributes = {
  .name = "TouchTask",
  .stack_size = 256 * 4,
  .priority = (osPriority_t) osPriorityBelowNormal7,
};
/* Definitions for TouchCalibKeyTa */
osThreadId_t TouchCalibKeyTaHandle;
const osThreadAttr_t TouchCalibKeyTa_attributes = {
  .name = "TouchCalibKeyTa",
  .stack_size = 256 * 4,
  .priority = (osPriority_t) osPriorityBelowNormal1,
};
/* Definitions for touch_mutex */
osMutexId_t touch_mutexHandle;
const osMutexAttr_t touch_mutex_attributes = {
  .name = "touch_mutex"
};
/* Definitions for xDataMutex */
osMutexId_t xDataMutexHandle;
const osMutexAttr_t xDataMutex_attributes = {
  .name = "xDataMutex"
};
/* Definitions for spi_mutex */
osMutexId_t spi_mutexHandle;
const osMutexAttr_t spi_mutex_attributes = {
  .name = "spi_mutex"
};
/* Definitions for xTPMutex */
osMutexId_t xTPMutexHandle;
const osMutexAttr_t xTPMutex_attributes = {
  .name = "xTPMutex"
};
/* USER CODE BEGIN PV */
uint8_t receivedChar;
//static FMC_SDRAM_CommandTypeDef Command;
/* -------------------------------------------------------------------------- */
/*                              Version variables                             */
/* -------------------------------------------------------------------------- */
const uint8_t Soft_Version[4] = { MAJOR, MINOR, PATCH , BUILD};
const uint8_t UI_Version[4] = { UIMAJOR, UIMINOR, UIPATCH , UIBUILD};
const uint8_t Board_Version[4] = { PCBMAJOR, PCBMINOR, PCBPATCH , PCBRELEASE};

/* -------------------------------------------------------------------------- */
/*                              RTC variables                                 */
/* -------------------------------------------------------------------------- */
char time[10];
char date[10];
uint8_t alarm =0;

/* -------------------------------------------------------------------------- */
/*                              Display variables                             */
/* -------------------------------------------------------------------------- */
uint32_t Brightness_LCD = 255;

/* -------------------------------------------------------------------------- */
/*                      Definitions Vendor_ID Queue                           */
/* -------------------------------------------------------------------------- */
/* Definitions for serialIDQueue */
osMessageQueueId_t serialIDQueueHandle;
const osMessageQueueAttr_t serialIDQueue_attributes = {
  .name = "serialIDQueue"
};

/* -------------------------------------------------------------------------- */
/*                         Definitions XPT2046 Queue                          */
/* -------------------------------------------------------------------------- */
#ifdef XPT2046_ENABLE
/* Definitions for uiQueue */
osMessageQueueId_t uiQueueHandle;
const osMessageQueueAttr_t uiQueue_attributes = {
  .name = "uiQueue"
};
#endif /* XPT2046_ENABLE */

/* -------------------------------------------------------------------------- */
/*                     Definitions File Browser Queue                         */
/* -------------------------------------------------------------------------- */
#ifdef FILE_BROWSER_ENABLE
//osMessageQueueId_t dirNoQueueHandle;								/* Definitions for dirNoQueue Directory amont*/
//const osMessageQueueAttr_t dirNoQueue_attributes = {
//  .name = "dirNoQueue"
//};
//
//osMessageQueueId_t fileNameQueueHandle;								/* Definitions for fileNameQueue File Name*/
//const osMessageQueueAttr_t fileNameQueue_attributes = {
//  .name = "fileNameQueue"
//};
//
//osMessageQueueId_t fileSizeQueueHandle;								/* Definitions for fileSizeQueue File Size*/
//const osMessageQueueAttr_t fileSizeQueue_attributes = {
//  .name = "fileSizeQueue"
//};
//
//osMessageQueueId_t dirNameQueueHandle;								/* Definitions for dirNameQueue Directory Name*/
//const osMessageQueueAttr_t dirNameQueue_attributes = {
//  .name = "dirNameQueue"
//};
//
//osMessageQueueId_t fileNoQueueHandle;								/* Definitions for fileNoQueue File amont*/
//const osMessageQueueAttr_t fileNoQueue_attributes = {
//  .name = "fileNoQueue"
//};
//
//osMessageQueueId_t openDirQueueHandle;								/* Definitions for openDirQueue Open Directory from GUI*/
//const osMessageQueueAttr_t openDirQueue_attributes = {
//  .name = "openDirQueue"
//};
//
//osMessageQueueId_t pathQueueHandle;									/* Definitions for pathQueue Address Path*/
//const osMessageQueueAttr_t pathQueue_attributes = {
//  .name = "pathQueue"
//};
//
//osMessageQueueId_t openFileCmdQueueHandle;							/* Definitions for readFileQueue Open File CMD from GUI*/
//const osMessageQueueAttr_t openFileCmdQueue_attributes = {
//  .name = "openFileCmdQueue"
//};
//
//osMessageQueueId_t sendFileNameQueueHandle;								/* Definitions for sendFileNameQueue send File Name to GUI*/
//const osMessageQueueAttr_t sendFileNameQueue_attributes = {
//  .name = "sendFileName"
//};
//
//osMessageQueueId_t readFileQueueHandle;								/* Definitions for readFileQueue Read File*/
//const osMessageQueueAttr_t readFileQueue_attributes = {
//  .name = "readFileQueue"
//};
//
//osMessageQueueId_t storageUsageQueueHandle;								/* Definitions for storageUsageQueue Get Storage Capacity*/
//const osMessageQueueAttr_t storageUsageQueue_attributes = {
//  .name = "storageUsageQueue"
//};
//
//osMessageQueueId_t eofQueueHandle;									/* Definitions for eofQueue End of File Read*/
//const osMessageQueueAttr_t eofQueue_attributes = {
//  .name = "eofQueue"
//};
//
//osMessageQueueId_t mkDirQueueHandle;									/* Definitions for mkDirQueue Make New Folder*/
//const osMessageQueueAttr_t mkDirQueue_attributes = {
//  .name = "mkDirQueue"
//};
//
//osMessageQueueId_t mkFilQueueHandle;									/* Definitions for mkDirQueue Make New File*/
//const osMessageQueueAttr_t mkFilQueue_attributes = {
//  .name = "mkFilQueue"
//};
//
//osMessageQueueId_t writeFileQueueHandle;							/* Definitions for writeFileQueue Write File*/
//const osMessageQueueAttr_t writeFileQueue_attributes = {
//  .name = "writeFileQueue"
//};
//
//osMessageQueueId_t writeFileDataQueueHandle;							/* Definitions for  writeFileDataQueue Write File Data*/
//const osMessageQueueAttr_t  writeFileDataQueue_attributes = {
//  .name = " writeFileDataQueue"
//};
//
//osMessageQueueId_t removeDirQueueHandle;									/* Definitions for removeDirQueue remove Folder*/
//const osMessageQueueAttr_t removeDirQueue_attributes = {
//  .name = "removeDirQueue"
//};
//
//osMessageQueueId_t errorQueueHandle;									/* Definitions for errorQueue send Error Dialog*/
//const osMessageQueueAttr_t errorQueue_attributes = {
//  .name = "errorQueue"
//};
//
//osMessageQueueId_t successDialogQueueHandle;							/* Definitions for successDialogQueue send Success Dialog*/
//const osMessageQueueAttr_t successDialogQueue_attributes = {
//  .name = "successDialogQueue"
//};

osMessageQueueId_t fileInfoQueueHandle;
const osMessageQueueAttr_t fileInfoQueue_attributes = {
  .name = "fileInfoQueue"
};

osMessageQueueId_t pathQueueHandle;
const osMessageQueueAttr_t pathQueue_attributes = {
  .name = "pathQueue"
};

osMessageQueueId_t storageUsageQueueHandle;
const osMessageQueueAttr_t storageUsageQueue_attributes = {
  .name = "storageUsageQueue"
};

osMessageQueueId_t fileContentQueueHandle;
const osMessageQueueAttr_t fileContentQueue_attributes = {
  .name = "fileContentQueue"
};

osMessageQueueId_t systemMessageQueueHandle;
const osMessageQueueAttr_t systemMessageQueue_attributes = {
  .name = "systemMessageQueue"
};

osMessageQueueId_t fileCommandQueueHandle;
const osMessageQueueAttr_t fileCommandQueue_attributes = {
  .name = "fileCommandQueue"
};

#endif /* FILE_BROWSER_ENABLE */

/* USER CODE END PV */

void SystemClock_Config(void);
void PeriphCommonClock_Config(void);
static void MPU_Config(void);
static void MX_GPIO_Init(void);
static void MX_DMA_Init(void);
static void MX_MDMA_Init(void);
static void MX_CRC_Init(void);
static void MX_USART1_UART_Init(void);
static void MX_RTC_Init(void);
static void MX_DMA2D_Init(void);
static void MX_ADC3_Init(void);
static void MX_I2C3_Init(void);
static void MX_LPTIM1_Init(void);
static void MX_TIM3_Init(void);
static void MX_I2C1_Init(void);
static void MX_FMC_Init(void);
static void MX_USART2_UART_Init(void);
static void MX_LTDC_Init(void);
static void MX_JPEG_Init(void);
static void MX_SDMMC1_SD_Init(void);
static void MX_TIM8_Init(void);
static void MX_TIM2_Init(void);
static void MX_RNG_Init(void);
void StartDefaultTask(void *argument);
extern void TouchGFX_Task(void *argument);
void StartTaskBrightnessLCD(void *argument);
extern void videoTaskFunc(void *argument);
void StartTaskuSD(void *argument);
void StartTouchTask(void *argument);
void StartTouchCalibKeyTask(void *argument);

/* USER CODE BEGIN PFP */
void Shutdown();
void HAL_GPIO_EXTI_Callback(uint16_t GPIO_Pin);
uint32_t getSerialNumber(void);
uint32_t get_random_number(void);
/* USER CODE END PFP */

int main(void)
{

  /* USER CODE BEGIN 1 */
	for(uint8_t i = 0; i < 8; i++)
	{
		NVIC->ICER[i]=0xFFFFFFFF;
		NVIC->ICPR[i]=0xFFFFFFFF;
	}
	RCC->CFGR = 0;
	SCB->VTOR = QSPI_BASE;
	__enable_irq();
	__set_PRIMASK(0);

	*((uint32_t*)0x51046108) = 1; /* DMA2D issue in cut 1.1 */
	*((uint32_t*)0x51008108) = 1; /* AXI SRAM issue in cut 1.2 */
  /* USER CODE END 1 */

  /* MPU Configuration--------------------------------------------------------*/
  MPU_Config();

  /* Enable the CPU Cache */

  /* Enable I-Cache---------------------------------------------------------*/
  SCB_EnableICache();

  /* Enable D-Cache---------------------------------------------------------*/
  SCB_EnableDCache();

  /* MCU Configuration--------------------------------------------------------*/

  /* Reset of all peripherals, Initializes the Flash interface and the Systick. */
  HAL_Init();

  /* Configure the system clock */
  SystemClock_Config();

  /* Configure the peripherals common clocks */
  PeriphCommonClock_Config();

  /* Initialize all configured peripherals */
  MX_GPIO_Init();
  MX_DMA_Init();
  MX_MDMA_Init();
  MX_CRC_Init();
  MX_USART1_UART_Init();
  MX_RTC_Init();
  MX_DMA2D_Init();
  MX_ADC3_Init();
  MX_I2C3_Init();
  MX_LPTIM1_Init();
  MX_TIM3_Init();
  MX_I2C1_Init();
  MX_FMC_Init();
  MX_USART2_UART_Init();
  MX_LTDC_Init();
  MX_JPEG_Init();
  MX_LIBJPEG_Init();
  MX_SDMMC1_SD_Init();
  MX_FATFS_Init();
  MX_TIM8_Init();
  MX_TIM2_Init();
  MX_RNG_Init();
  MX_TouchGFX_Init();
  /* Call PreOsInit function */
  MX_TouchGFX_PreOSInit();
  /* USER CODE BEGIN 2 */
  HAL_TIM_Base_Start(&htim2);
  delayInit();
  /* USER CODE END 2 */

  /* Init scheduler */
  osKernelInitialize();
  /* Create the mutex(es) */
  /* creation of touch_mutex */
  touch_mutexHandle = osMutexNew(&touch_mutex_attributes);

  /* creation of xDataMutex */
  xDataMutexHandle = osMutexNew(&xDataMutex_attributes);

  /* creation of spi_mutex */
  spi_mutexHandle = osMutexNew(&spi_mutex_attributes);

  /* creation of xTPMutex */
  xTPMutexHandle = osMutexNew(&xTPMutex_attributes);

  /* USER CODE BEGIN RTOS_MUTEX */
  /* add mutexes, ... */

//  metricsMutexHandle = osMutexNew(&metricsMutex_attributes);
  /* USER CODE END RTOS_MUTEX */

  /* USER CODE BEGIN RTOS_QUEUES */
  /* add queues, ... */
  /* creation of adcQueue */
//  adcQueueHandle = osMessageQueueNew (4, sizeof(ADC_Data_t), &adcQueue_attributes);
//
//  batteryDataQueueHandle = (4, sizeof(BatteryState), &batteryDataQueue_attributes);		/* Definitions for mAhBatteryQueue send Battery mAh*/

  /* creation of serialIDQueue */
  serialIDQueueHandle = osMessageQueueNew (1, sizeof(int), &serialIDQueue_attributes);

#ifdef XPT2046_ENABLE
  /* creation of uiQueue */
  uiQueueHandle = osMessageQueueNew (10, sizeof(UI_Command_t), &uiQueue_attributes);
#endif /* XPT2046_ENABLE */

#ifdef FILE_BROWSER_ENABLE
//  dirNoQueueHandle = osMessageQueueNew (1, sizeof(int), &dirNoQueue_attributes);  						/* creation of dirNoQueue Directory amont */
//
//  fileNameQueueHandle = osMessageQueueNew (1, sizeof(char[MAX_FILE_NAME_LEN]), &fileNameQueue_attributes);  			/* creation of fileNameQueue File Name*/
//
//  fileSizeQueueHandle = osMessageQueueNew (1, sizeof(int), &fileSizeQueue_attributes);  				/* creation of fileSizeQueue File Size*/
//
//  dirNameQueueHandle = osMessageQueueNew (1, sizeof(char[MAX_DIR_NAME_LEN]), &dirNameQueue_attributes);  			/* creation of dirNameQueue Directory Name*/
//
//  fileNoQueueHandle = osMessageQueueNew (1, sizeof(int), &fileNoQueue_attributes);  					/* creation of fileNoQueue File amont*/
//
//  openDirQueueHandle = osMessageQueueNew (1, sizeof(char[MAX_OPEN_DIR_NAME_LEN]), &openDirQueue_attributes);  			/* creation of openDirQueue Open Directory from GUI*/
//
//  pathQueueHandle = osMessageQueueNew (1, sizeof(char[100]), &pathQueue_attributes);					/* creation of pathQueue Address Path*/
//
//  openFileCmdQueueHandle = osMessageQueueNew (1, sizeof(char[100]), &openFileCmdQueue_attributes);		/* creation of openFileCmdQueue Open File CMD from GUI*/
//
//  sendFileNameQueueHandle = osMessageQueueNew (1, sizeof(char[100]), &sendFileNameQueue_attributes);	/* Definitions for sendFileNameQueue send File Name to GUI*/
//
//  readFileQueueHandle = osMessageQueueNew (1, sizeof(char[MAX_READ_BUFF_SIZE]), &readFileQueue_attributes);			/* creation of readFileQueue Read File*/
//
//  storageUsageQueueHandle = osMessageQueueNew (2, sizeof(long), &storageUsageQueue_attributes);			/* creation of readFileQueue Read File*/
//
//  eofQueueHandle = osMessageQueueNew (1, sizeof(bool), &eofQueue_attributes);							/* creation of eofQueue End of File Read*/
//
//  mkDirQueueHandle = osMessageQueueNew (1, sizeof(char[20]), &mkDirQueue_attributes);					/* Definitions for mkDirQueue Make New Folder*/
//
//  mkFilQueueHandle = osMessageQueueNew (1, sizeof(char[20]), &mkDirQueue_attributes);					/* Definitions for mkDirQueue Make New File*/
//
//  writeFileQueueHandle = osMessageQueueNew (1, sizeof(char[20]), &writeFileQueue_attributes);			/* Definitions for writeFileQueue Write File*/
//
//  writeFileDataQueueHandle = osMessageQueueNew (1, sizeof(char[MAX_WRITE_BUFF_SIZE]), &writeFileDataQueue_attributes);			/* Definitions for writeFileQueue Write File*/
//
//  removeDirQueueHandle = osMessageQueueNew (1, sizeof(char[100]), &removeDirQueue_attributes);			/* Definitions for removeDirQueue Remove Folder*/
//
//  errorQueueHandle = osMessageQueueNew (1, sizeof(char[50]), &errorQueue_attributes);					/* Definitions for errorQueue send Error Dialog*/
//
//  successDialogQueueHandle = osMessageQueueNew (1, sizeof(char[50]), &successDialogQueue_attributes);	/* Definitions for successDialogQueue send Success Dialog*/

  // Create queues
  fileInfoQueueHandle = osMessageQueueNew(20, sizeof(FileInfo), &fileInfoQueue_attributes);
  pathQueueHandle = osMessageQueueNew(5, MAX_PATH_LEN, &pathQueue_attributes);
  storageUsageQueueHandle = osMessageQueueNew(3, 3*sizeof(uint32_t), &storageUsageQueue_attributes);
  fileContentQueueHandle = osMessageQueueNew(10, MAX_READ_BUFF_SIZE, &fileContentQueue_attributes);
  systemMessageQueueHandle = osMessageQueueNew(10, sizeof(SystemMessage), &systemMessageQueue_attributes);
  fileCommandQueueHandle = osMessageQueueNew(10, sizeof(FileCommand), &fileCommandQueue_attributes);

#endif /* FILE_BROWSER_ENABLE */

  /* creation of hx711Queue */
//  hx711QueueHandle = osMessageQueueNew (12, sizeof(HX711_QueueData_t), &hx711Queue_attributes);
  /* creation of metricsQueue */
//  metricsQueueHandle = osMessageQueueNew (10, sizeof(SystemMetrics_t), &metricsQueue_attributes);

  /* creation of weightsQueue */
//  weightsQueueHandle = osMessageQueueNew (10, sizeof(ChannelWeights_t), &weightsQueue_attributes);

  /* USER CODE END RTOS_QUEUES */

  /* Create the thread(s) */
  /* creation of defaultTask */
  defaultTaskHandle = osThreadNew(StartDefaultTask, NULL, &defaultTask_attributes);

  /* creation of TouchGFXTask */
  TouchGFXTaskHandle = osThreadNew(TouchGFX_Task, NULL, &TouchGFXTask_attributes);

  /* creation of brightnessLcdTa */
  brightnessLcdTaHandle = osThreadNew(StartTaskBrightnessLCD, NULL, &brightnessLcdTa_attributes);

  /* creation of VideoTask */
  VideoTaskHandle = osThreadNew(videoTaskFunc, NULL, &VideoTask_attributes);

  /* creation of uSDTask */
  uSDTaskHandle = osThreadNew(StartTaskuSD, NULL, &uSDTask_attributes);

  /* creation of TouchTask */
  TouchTaskHandle = osThreadNew(StartTouchTask, NULL, &TouchTask_attributes);

  /* creation of TouchCalibKeyTa */
  TouchCalibKeyTaHandle = osThreadNew(StartTouchCalibKeyTask, NULL, &TouchCalibKeyTa_attributes);

  /* Start scheduler */
  osKernelStart();

  /* We should never get here as control is now taken by the scheduler */

  /* Infinite loop */
  while (1)
  {

  }
}

void SystemClock_Config(void)
{
  RCC_OscInitTypeDef RCC_OscInitStruct = {0};
  RCC_ClkInitTypeDef RCC_ClkInitStruct = {0};

  /** Supply configuration update enable
  */
  HAL_PWREx_ConfigSupply(PWR_LDO_SUPPLY);

  /** Configure the main internal regulator output voltage
  */
  __HAL_PWR_VOLTAGESCALING_CONFIG(PWR_REGULATOR_VOLTAGE_SCALE0);

  while(!__HAL_PWR_GET_FLAG(PWR_FLAG_VOSRDY)) {}

  /** Configure LSE Drive Capability
  */
  HAL_PWR_EnableBkUpAccess();
  __HAL_RCC_LSEDRIVE_CONFIG(RCC_LSEDRIVE_HIGH);

  /** Initializes the RCC Oscillators according to the specified parameters
  * in the RCC_OscInitTypeDef structure.
  */
  RCC_OscInitStruct.OscillatorType = RCC_OSCILLATORTYPE_HSI48|RCC_OSCILLATORTYPE_HSI
                              |RCC_OSCILLATORTYPE_HSE|RCC_OSCILLATORTYPE_LSE;
  RCC_OscInitStruct.HSEState = RCC_HSE_ON;
  RCC_OscInitStruct.LSEState = RCC_LSE_ON;
  RCC_OscInitStruct.HSIState = RCC_HSI_DIV1;
  RCC_OscInitStruct.HSICalibrationValue = RCC_HSICALIBRATION_DEFAULT;
  RCC_OscInitStruct.HSI48State = RCC_HSI48_ON;
  RCC_OscInitStruct.PLL.PLLState = RCC_PLL_ON;
  RCC_OscInitStruct.PLL.PLLSource = RCC_PLLSOURCE_HSE;
  RCC_OscInitStruct.PLL.PLLM = 5;
  RCC_OscInitStruct.PLL.PLLN = 192;
  RCC_OscInitStruct.PLL.PLLP = 2;
  RCC_OscInitStruct.PLL.PLLQ = 8;
  RCC_OscInitStruct.PLL.PLLR = 4;
  RCC_OscInitStruct.PLL.PLLRGE = RCC_PLL1VCIRANGE_2;
  RCC_OscInitStruct.PLL.PLLVCOSEL = RCC_PLL1VCOWIDE;
  RCC_OscInitStruct.PLL.PLLFRACN = 0;
  if (HAL_RCC_OscConfig(&RCC_OscInitStruct) != HAL_OK)
  {
    Error_Handler();
  }

  /** Initializes the CPU, AHB and APB buses clocks
  */
  RCC_ClkInitStruct.ClockType = RCC_CLOCKTYPE_HCLK|RCC_CLOCKTYPE_SYSCLK
                              |RCC_CLOCKTYPE_PCLK1|RCC_CLOCKTYPE_PCLK2
                              |RCC_CLOCKTYPE_D3PCLK1|RCC_CLOCKTYPE_D1PCLK1;
  RCC_ClkInitStruct.SYSCLKSource = RCC_SYSCLKSOURCE_PLLCLK;
  RCC_ClkInitStruct.SYSCLKDivider = RCC_SYSCLK_DIV1;
  RCC_ClkInitStruct.AHBCLKDivider = RCC_HCLK_DIV2;
  RCC_ClkInitStruct.APB3CLKDivider = RCC_APB3_DIV2;
  RCC_ClkInitStruct.APB1CLKDivider = RCC_APB1_DIV2;
  RCC_ClkInitStruct.APB2CLKDivider = RCC_APB2_DIV2;
  RCC_ClkInitStruct.APB4CLKDivider = RCC_APB4_DIV2;

  if (HAL_RCC_ClockConfig(&RCC_ClkInitStruct, FLASH_LATENCY_4) != HAL_OK)
  {
    Error_Handler();
  }
}

void PeriphCommonClock_Config(void)
{
  RCC_PeriphCLKInitTypeDef PeriphClkInitStruct = {0};

  /** Initializes the peripherals clock
  */
  PeriphClkInitStruct.PeriphClockSelection = RCC_PERIPHCLK_CKPER;
  PeriphClkInitStruct.CkperClockSelection = RCC_CLKPSOURCE_HSI;
  if (HAL_RCCEx_PeriphCLKConfig(&PeriphClkInitStruct) != HAL_OK)
  {
    Error_Handler();
  }
}

static void MX_ADC3_Init(void)
{

  ADC_ChannelConfTypeDef sConfig = {0};

  /** Common config
  */
  hadc3.Instance = ADC3;
  hadc3.Init.ClockPrescaler = ADC_CLOCK_ASYNC_DIV6;
  hadc3.Init.Resolution = ADC_RESOLUTION_16B;
  hadc3.Init.ScanConvMode = ADC_SCAN_ENABLE;
  hadc3.Init.EOCSelection = ADC_EOC_SINGLE_CONV;
  hadc3.Init.LowPowerAutoWait = DISABLE;
  hadc3.Init.ContinuousConvMode = DISABLE;
  hadc3.Init.NbrOfConversion = 3;
  hadc3.Init.DiscontinuousConvMode = DISABLE;
  hadc3.Init.ExternalTrigConv = ADC_EXTERNALTRIG_T8_TRGO;
  hadc3.Init.ExternalTrigConvEdge = ADC_EXTERNALTRIGCONVEDGE_RISING;
  hadc3.Init.ConversionDataManagement = ADC_CONVERSIONDATA_DMA_CIRCULAR;
  hadc3.Init.Overrun = ADC_OVR_DATA_PRESERVED;
  hadc3.Init.LeftBitShift = ADC_LEFTBITSHIFT_NONE;
  hadc3.Init.OversamplingMode = ENABLE;
  hadc3.Init.Oversampling.Ratio = 1024;
  hadc3.Init.Oversampling.RightBitShift = ADC_RIGHTBITSHIFT_10;
  hadc3.Init.Oversampling.TriggeredMode = ADC_TRIGGEREDMODE_SINGLE_TRIGGER;
  hadc3.Init.Oversampling.OversamplingStopReset = ADC_REGOVERSAMPLING_CONTINUED_MODE;
  if (HAL_ADC_Init(&hadc3) != HAL_OK)
  {
    Error_Handler();
  }

  /** Configure Regular Channel
  */
  sConfig.Channel = ADC_CHANNEL_VBAT;
  sConfig.Rank = ADC_REGULAR_RANK_1;
  sConfig.SamplingTime = ADC_SAMPLETIME_64CYCLES_5;
  sConfig.SingleDiff = ADC_SINGLE_ENDED;
  sConfig.OffsetNumber = ADC_OFFSET_NONE;
  sConfig.Offset = 0;
  sConfig.OffsetSignedSaturation = DISABLE;
  if (HAL_ADC_ConfigChannel(&hadc3, &sConfig) != HAL_OK)
  {
    Error_Handler();
  }

  /** Configure Regular Channel
  */
  sConfig.Channel = ADC_CHANNEL_TEMPSENSOR;
  sConfig.Rank = ADC_REGULAR_RANK_2;
  if (HAL_ADC_ConfigChannel(&hadc3, &sConfig) != HAL_OK)
  {
    Error_Handler();
  }

  /** Configure Regular Channel
  */
  sConfig.Channel = ADC_CHANNEL_VREFINT;
  sConfig.Rank = ADC_REGULAR_RANK_3;
  if (HAL_ADC_ConfigChannel(&hadc3, &sConfig) != HAL_OK)
  {
    Error_Handler();
  }

}

static void MX_CRC_Init(void)
{

  hcrc.Instance = CRC;
  hcrc.Init.DefaultPolynomialUse = DEFAULT_POLYNOMIAL_ENABLE;
  hcrc.Init.DefaultInitValueUse = DEFAULT_INIT_VALUE_ENABLE;
  hcrc.Init.InputDataInversionMode = CRC_INPUTDATA_INVERSION_NONE;
  hcrc.Init.OutputDataInversionMode = CRC_OUTPUTDATA_INVERSION_DISABLE;
  hcrc.InputDataFormat = CRC_INPUTDATA_FORMAT_BYTES;
  if (HAL_CRC_Init(&hcrc) != HAL_OK)
  {
    Error_Handler();
  }

}

static void MX_DMA2D_Init(void)
{

  hdma2d.Instance = DMA2D;
  hdma2d.Init.Mode = DMA2D_M2M;
  hdma2d.Init.ColorMode = DMA2D_OUTPUT_RGB565;
  hdma2d.Init.OutputOffset = 0;
  hdma2d.LayerCfg[1].InputOffset = 0;
  hdma2d.LayerCfg[1].InputColorMode = DMA2D_INPUT_RGB565;
  hdma2d.LayerCfg[1].AlphaMode = DMA2D_NO_MODIF_ALPHA;
  hdma2d.LayerCfg[1].InputAlpha = 0;
  hdma2d.LayerCfg[1].AlphaInverted = DMA2D_REGULAR_ALPHA;
  hdma2d.LayerCfg[1].RedBlueSwap = DMA2D_RB_REGULAR;
  hdma2d.LayerCfg[1].ChromaSubSampling = DMA2D_NO_CSS;
  if (HAL_DMA2D_Init(&hdma2d) != HAL_OK)
  {
    Error_Handler();
  }
  if (HAL_DMA2D_ConfigLayer(&hdma2d, 1) != HAL_OK)
  {
    Error_Handler();
  }

}

static void MX_I2C1_Init(void)
{

  hi2c1.Instance = I2C1;
  hi2c1.Init.Timing = 0x00602173;
  hi2c1.Init.OwnAddress1 = 0;
  hi2c1.Init.AddressingMode = I2C_ADDRESSINGMODE_7BIT;
  hi2c1.Init.DualAddressMode = I2C_DUALADDRESS_DISABLE;
  hi2c1.Init.OwnAddress2 = 0;
  hi2c1.Init.OwnAddress2Masks = I2C_OA2_NOMASK;
  hi2c1.Init.GeneralCallMode = I2C_GENERALCALL_DISABLE;
  hi2c1.Init.NoStretchMode = I2C_NOSTRETCH_DISABLE;
  if (HAL_I2C_Init(&hi2c1) != HAL_OK)
  {
    Error_Handler();
  }

  /** Configure Analogue filter
  */
  if (HAL_I2CEx_ConfigAnalogFilter(&hi2c1, I2C_ANALOGFILTER_ENABLE) != HAL_OK)
  {
    Error_Handler();
  }

  /** Configure Digital filter
  */
  if (HAL_I2CEx_ConfigDigitalFilter(&hi2c1, 0) != HAL_OK)
  {
    Error_Handler();
  }

}

static void MX_I2C3_Init(void)
{

  hi2c3.Instance = I2C3;
  hi2c3.Init.Timing = 0x00602173;
  hi2c3.Init.OwnAddress1 = 0;
  hi2c3.Init.AddressingMode = I2C_ADDRESSINGMODE_7BIT;
  hi2c3.Init.DualAddressMode = I2C_DUALADDRESS_DISABLE;
  hi2c3.Init.OwnAddress2 = 0;
  hi2c3.Init.OwnAddress2Masks = I2C_OA2_NOMASK;
  hi2c3.Init.GeneralCallMode = I2C_GENERALCALL_ENABLE;
  hi2c3.Init.NoStretchMode = I2C_NOSTRETCH_DISABLE;
  if (HAL_I2C_Init(&hi2c3) != HAL_OK)
  {
    Error_Handler();
  }

  /** Configure Analogue filter
  */
  if (HAL_I2CEx_ConfigAnalogFilter(&hi2c3, I2C_ANALOGFILTER_ENABLE) != HAL_OK)
  {
    Error_Handler();
  }

  /** Configure Digital filter
  */
  if (HAL_I2CEx_ConfigDigitalFilter(&hi2c3, 0) != HAL_OK)
  {
    Error_Handler();
  }

}

static void MX_JPEG_Init(void)
{

  hjpeg.Instance = JPEG;
  if (HAL_JPEG_Init(&hjpeg) != HAL_OK)
  {
    Error_Handler();
  }

}

static void MX_LPTIM1_Init(void)
{

  hlptim1.Instance = LPTIM1;
  hlptim1.Init.Clock.Source = LPTIM_CLOCKSOURCE_APBCLOCK_LPOSC;
  hlptim1.Init.Clock.Prescaler = LPTIM_PRESCALER_DIV32;
  hlptim1.Init.Trigger.Source = LPTIM_TRIGSOURCE_SOFTWARE;
  hlptim1.Init.OutputPolarity = LPTIM_OUTPUTPOLARITY_HIGH;
  hlptim1.Init.UpdateMode = LPTIM_UPDATE_IMMEDIATE;
  hlptim1.Init.CounterSource = LPTIM_COUNTERSOURCE_INTERNAL;
  hlptim1.Init.Input1Source = LPTIM_INPUT1SOURCE_GPIO;
  hlptim1.Init.Input2Source = LPTIM_INPUT2SOURCE_GPIO;
  if (HAL_LPTIM_Init(&hlptim1) != HAL_OK)
  {
    Error_Handler();
  }

}

static void MX_LTDC_Init(void)
{

  LTDC_LayerCfgTypeDef pLayerCfg = {0};

  hltdc.Instance = LTDC;
  hltdc.Init.HSPolarity = LTDC_HSPOLARITY_AL;
  hltdc.Init.VSPolarity = LTDC_VSPOLARITY_AL;
  hltdc.Init.DEPolarity = LTDC_DEPOLARITY_AL;
  hltdc.Init.PCPolarity = LTDC_PCPOLARITY_IPC;
  hltdc.Init.HorizontalSync = 39;
  hltdc.Init.VerticalSync = 9;
  hltdc.Init.AccumulatedHBP = 127;
  hltdc.Init.AccumulatedVBP = 29;
  hltdc.Init.AccumulatedActiveW = 1151;
  hltdc.Init.AccumulatedActiveH = 629;
  hltdc.Init.TotalWidth = 1191;
  hltdc.Init.TotalHeigh = 649;
  hltdc.Init.Backcolor.Blue = 0;
  hltdc.Init.Backcolor.Green = 0;
  hltdc.Init.Backcolor.Red = 0;
  if (HAL_LTDC_Init(&hltdc) != HAL_OK)
  {
    Error_Handler();
  }
  pLayerCfg.WindowX0 = 0;
  pLayerCfg.WindowX1 = 1024;
  pLayerCfg.WindowY0 = 0;
  pLayerCfg.WindowY1 = 600;
  pLayerCfg.PixelFormat = LTDC_PIXEL_FORMAT_RGB565;
  pLayerCfg.Alpha = 255;
  pLayerCfg.Alpha0 = 0;
  pLayerCfg.BlendingFactor1 = LTDC_BLENDING_FACTOR1_CA;
  pLayerCfg.BlendingFactor2 = LTDC_BLENDING_FACTOR2_CA;
  pLayerCfg.FBStartAdress = 0;
  pLayerCfg.ImageWidth = 1024;
  pLayerCfg.ImageHeight = 600;
  pLayerCfg.Backcolor.Blue = 255;
  pLayerCfg.Backcolor.Green = 0;
  pLayerCfg.Backcolor.Red = 0;
  if (HAL_LTDC_ConfigLayer(&hltdc, &pLayerCfg, 0) != HAL_OK)
  {
    Error_Handler();
  }

}

static void MX_RNG_Init(void)
{

  hrng.Instance = RNG;
  hrng.Init.ClockErrorDetection = RNG_CED_ENABLE;
  if (HAL_RNG_Init(&hrng) != HAL_OK)
  {
    Error_Handler();
  }

}

static void MX_RTC_Init(void)
{

  RTC_TimeTypeDef sTime = {0};
  RTC_DateTypeDef sDate = {0};

  /** Initialize RTC Only
  */
  hrtc.Instance = RTC;
  hrtc.Init.HourFormat = RTC_HOURFORMAT_24;
  hrtc.Init.AsynchPrediv = 127;
  hrtc.Init.SynchPrediv = 255;
  hrtc.Init.OutPut = RTC_OUTPUT_DISABLE;
  hrtc.Init.OutPutPolarity = RTC_OUTPUT_POLARITY_HIGH;
  hrtc.Init.OutPutType = RTC_OUTPUT_TYPE_OPENDRAIN;
  hrtc.Init.OutPutRemap = RTC_OUTPUT_REMAP_NONE;
  if (HAL_RTC_Init(&hrtc) != HAL_OK)
  {
    Error_Handler();
  }

  /* USER CODE BEGIN Check_RTC_BKUP */
  if(HAL_RTCEx_BKUPRead(&hrtc, RTC_BKP_DR1) != 0x32F2)
    {
  /* USER CODE END Check_RTC_BKUP */

  /** Initialize RTC and set the Time and Date
  */
  sTime.Hours = 0x0;
  sTime.Minutes = 0x0;
  sTime.Seconds = 0x0;
  sTime.DayLightSaving = RTC_DAYLIGHTSAVING_NONE;
  sTime.StoreOperation = RTC_STOREOPERATION_RESET;
  if (HAL_RTC_SetTime(&hrtc, &sTime, RTC_FORMAT_BCD) != HAL_OK)
  {
    Error_Handler();
  }
  sDate.WeekDay = RTC_WEEKDAY_MONDAY;
  sDate.Month = RTC_MONTH_JANUARY;
  sDate.Date = 0x1;
  sDate.Year = 0x20;

  if (HAL_RTC_SetDate(&hrtc, &sDate, RTC_FORMAT_BCD) != HAL_OK)
  {
    Error_Handler();
  }
  /* USER CODE BEGIN RTC_Init 2 */
    }
  HAL_RTCEx_BKUPWrite(&hrtc, RTC_BKP_DR1, 0x32F2);  // backup register
  /* USER CODE END RTC_Init 2 */

}

static void MX_SDMMC1_SD_Init(void)
{

  hsd1.Instance = SDMMC1;
  hsd1.Init.ClockEdge = SDMMC_CLOCK_EDGE_RISING;
  hsd1.Init.ClockPowerSave = SDMMC_CLOCK_POWER_SAVE_DISABLE;
  hsd1.Init.BusWide = SDMMC_BUS_WIDE_4B;
  hsd1.Init.HardwareFlowControl = SDMMC_HARDWARE_FLOW_CONTROL_DISABLE;
  hsd1.Init.ClockDiv = 8;

}

static void MX_TIM2_Init(void)
{

  TIM_ClockConfigTypeDef sClockSourceConfig = {0};
  TIM_MasterConfigTypeDef sMasterConfig = {0};

  htim2.Instance = TIM2;
  htim2.Init.Prescaler = 240-1;
  htim2.Init.CounterMode = TIM_COUNTERMODE_UP;
  htim2.Init.Period = 0xffffffff-1;
  htim2.Init.ClockDivision = TIM_CLOCKDIVISION_DIV1;
  htim2.Init.AutoReloadPreload = TIM_AUTORELOAD_PRELOAD_DISABLE;
  if (HAL_TIM_Base_Init(&htim2) != HAL_OK)
  {
    Error_Handler();
  }
  sClockSourceConfig.ClockSource = TIM_CLOCKSOURCE_INTERNAL;
  if (HAL_TIM_ConfigClockSource(&htim2, &sClockSourceConfig) != HAL_OK)
  {
    Error_Handler();
  }
  sMasterConfig.MasterOutputTrigger = TIM_TRGO_RESET;
  sMasterConfig.MasterSlaveMode = TIM_MASTERSLAVEMODE_DISABLE;
  if (HAL_TIMEx_MasterConfigSynchronization(&htim2, &sMasterConfig) != HAL_OK)
  {
    Error_Handler();
  }

}

static void MX_TIM3_Init(void)
{

  TIM_ClockConfigTypeDef sClockSourceConfig = {0};
  TIM_MasterConfigTypeDef sMasterConfig = {0};
  TIM_OC_InitTypeDef sConfigOC = {0};

  htim3.Instance = TIM3;
  htim3.Init.Prescaler = 0;
  htim3.Init.CounterMode = TIM_COUNTERMODE_UP;
  htim3.Init.Period = 255;
  htim3.Init.ClockDivision = TIM_CLOCKDIVISION_DIV1;
  htim3.Init.AutoReloadPreload = TIM_AUTORELOAD_PRELOAD_ENABLE;
  if (HAL_TIM_Base_Init(&htim3) != HAL_OK)
  {
    Error_Handler();
  }
  sClockSourceConfig.ClockSource = TIM_CLOCKSOURCE_INTERNAL;
  if (HAL_TIM_ConfigClockSource(&htim3, &sClockSourceConfig) != HAL_OK)
  {
    Error_Handler();
  }
  if (HAL_TIM_PWM_Init(&htim3) != HAL_OK)
  {
    Error_Handler();
  }
  sMasterConfig.MasterOutputTrigger = TIM_TRGO_RESET;
  sMasterConfig.MasterSlaveMode = TIM_MASTERSLAVEMODE_DISABLE;
  if (HAL_TIMEx_MasterConfigSynchronization(&htim3, &sMasterConfig) != HAL_OK)
  {
    Error_Handler();
  }
  sConfigOC.OCMode = TIM_OCMODE_PWM1;
  sConfigOC.Pulse = 0;
  sConfigOC.OCPolarity = TIM_OCPOLARITY_HIGH;
  sConfigOC.OCFastMode = TIM_OCFAST_DISABLE;
  if (HAL_TIM_PWM_ConfigChannel(&htim3, &sConfigOC, TIM_CHANNEL_2) != HAL_OK)
  {
    Error_Handler();
  }
  HAL_TIM_MspPostInit(&htim3);

}

static void MX_TIM8_Init(void)
{

  TIM_ClockConfigTypeDef sClockSourceConfig = {0};
  TIM_MasterConfigTypeDef sMasterConfig = {0};

  htim8.Instance = TIM8;
  htim8.Init.Prescaler = 24000-1;
  htim8.Init.CounterMode = TIM_COUNTERMODE_UP;
  htim8.Init.Period = 1000-1;
  htim8.Init.ClockDivision = TIM_CLOCKDIVISION_DIV1;
  htim8.Init.RepetitionCounter = 0;
  htim8.Init.AutoReloadPreload = TIM_AUTORELOAD_PRELOAD_DISABLE;
  if (HAL_TIM_Base_Init(&htim8) != HAL_OK)
  {
    Error_Handler();
  }
  sClockSourceConfig.ClockSource = TIM_CLOCKSOURCE_INTERNAL;
  if (HAL_TIM_ConfigClockSource(&htim8, &sClockSourceConfig) != HAL_OK)
  {
    Error_Handler();
  }
  sMasterConfig.MasterOutputTrigger = TIM_TRGO_UPDATE;
  sMasterConfig.MasterOutputTrigger2 = TIM_TRGO2_RESET;
  sMasterConfig.MasterSlaveMode = TIM_MASTERSLAVEMODE_DISABLE;
  if (HAL_TIMEx_MasterConfigSynchronization(&htim8, &sMasterConfig) != HAL_OK)
  {
    Error_Handler();
  }

}

static void MX_USART1_UART_Init(void)
{

  huart1.Instance = USART1;
  huart1.Init.BaudRate = 115200;
  huart1.Init.WordLength = UART_WORDLENGTH_8B;
  huart1.Init.StopBits = UART_STOPBITS_1;
  huart1.Init.Parity = UART_PARITY_NONE;
  huart1.Init.Mode = UART_MODE_TX_RX;
  huart1.Init.HwFlowCtl = UART_HWCONTROL_NONE;
  huart1.Init.OverSampling = UART_OVERSAMPLING_8;
  huart1.Init.OneBitSampling = UART_ONE_BIT_SAMPLE_DISABLE;
  huart1.Init.ClockPrescaler = UART_PRESCALER_DIV1;
  huart1.AdvancedInit.AdvFeatureInit = UART_ADVFEATURE_NO_INIT;
  if (HAL_UART_Init(&huart1) != HAL_OK)
  {
    Error_Handler();
  }
  if (HAL_UARTEx_SetTxFifoThreshold(&huart1, UART_TXFIFO_THRESHOLD_1_8) != HAL_OK)
  {
    Error_Handler();
  }
  if (HAL_UARTEx_SetRxFifoThreshold(&huart1, UART_RXFIFO_THRESHOLD_1_8) != HAL_OK)
  {
    Error_Handler();
  }
  if (HAL_UARTEx_DisableFifoMode(&huart1) != HAL_OK)
  {
    Error_Handler();
  }

}

static void MX_USART2_UART_Init(void)
{

  huart2.Instance = USART2;
  huart2.Init.BaudRate = 115200;
  huart2.Init.WordLength = UART_WORDLENGTH_8B;
  huart2.Init.StopBits = UART_STOPBITS_1;
  huart2.Init.Parity = UART_PARITY_NONE;
  huart2.Init.Mode = UART_MODE_TX_RX;
  huart2.Init.HwFlowCtl = UART_HWCONTROL_NONE;
  huart2.Init.OverSampling = UART_OVERSAMPLING_8;
  huart2.Init.OneBitSampling = UART_ONE_BIT_SAMPLE_DISABLE;
  huart2.Init.ClockPrescaler = UART_PRESCALER_DIV1;
  huart2.AdvancedInit.AdvFeatureInit = UART_ADVFEATURE_NO_INIT;
  if (HAL_UART_Init(&huart2) != HAL_OK)
  {
    Error_Handler();
  }
  if (HAL_UARTEx_SetTxFifoThreshold(&huart2, UART_TXFIFO_THRESHOLD_1_8) != HAL_OK)
  {
    Error_Handler();
  }
  if (HAL_UARTEx_SetRxFifoThreshold(&huart2, UART_RXFIFO_THRESHOLD_1_8) != HAL_OK)
  {
    Error_Handler();
  }
  if (HAL_UARTEx_DisableFifoMode(&huart2) != HAL_OK)
  {
    Error_Handler();
  }

}

static void MX_DMA_Init(void)
{

  /* DMA controller clock enable */
  __HAL_RCC_DMA1_CLK_ENABLE();
  __HAL_RCC_DMA2_CLK_ENABLE();

  /* DMA interrupt init */
  /* DMA1_Stream1_IRQn interrupt configuration */
  HAL_NVIC_SetPriority(DMA1_Stream1_IRQn, 5, 0);
  HAL_NVIC_EnableIRQ(DMA1_Stream1_IRQn);
  /* DMA1_Stream2_IRQn interrupt configuration */
  HAL_NVIC_SetPriority(DMA1_Stream2_IRQn, 5, 0);
  HAL_NVIC_EnableIRQ(DMA1_Stream2_IRQn);
  /* DMA1_Stream4_IRQn interrupt configuration */
  HAL_NVIC_SetPriority(DMA1_Stream4_IRQn, 5, 0);
  HAL_NVIC_EnableIRQ(DMA1_Stream4_IRQn);
  /* DMA1_Stream5_IRQn interrupt configuration */
  HAL_NVIC_SetPriority(DMA1_Stream5_IRQn, 5, 0);
  HAL_NVIC_EnableIRQ(DMA1_Stream5_IRQn);
  /* DMA1_Stream6_IRQn interrupt configuration */
  HAL_NVIC_SetPriority(DMA1_Stream6_IRQn, 5, 0);
  HAL_NVIC_EnableIRQ(DMA1_Stream6_IRQn);
  /* DMA1_Stream7_IRQn interrupt configuration */
  HAL_NVIC_SetPriority(DMA1_Stream7_IRQn, 5, 0);
  HAL_NVIC_EnableIRQ(DMA1_Stream7_IRQn);
  /* DMA2_Stream0_IRQn interrupt configuration */
  HAL_NVIC_SetPriority(DMA2_Stream0_IRQn, 5, 0);
  HAL_NVIC_EnableIRQ(DMA2_Stream0_IRQn);
  /* DMA2_Stream1_IRQn interrupt configuration */
  HAL_NVIC_SetPriority(DMA2_Stream1_IRQn, 5, 0);
  HAL_NVIC_EnableIRQ(DMA2_Stream1_IRQn);

}

/**
  * Enable MDMA controller clock
  */
static void MX_MDMA_Init(void)
{

  /* MDMA controller clock enable */
  __HAL_RCC_MDMA_CLK_ENABLE();
  /* Local variables */

  /* MDMA interrupt initialization */
  /* MDMA_IRQn interrupt configuration */
  HAL_NVIC_SetPriority(MDMA_IRQn, 5, 0);
  HAL_NVIC_EnableIRQ(MDMA_IRQn);

}

/* FMC initialization function */
static void MX_FMC_Init(void)
{

  FMC_SDRAM_TimingTypeDef SdramTiming = {0};

  /** Perform the SDRAM1 memory initialization sequence
  */
  hsdram1.Instance = FMC_SDRAM_DEVICE;
  /* hsdram1.Init */
  hsdram1.Init.SDBank = FMC_SDRAM_BANK1;
  hsdram1.Init.ColumnBitsNumber = FMC_SDRAM_COLUMN_BITS_NUM_9;
  hsdram1.Init.RowBitsNumber = FMC_SDRAM_ROW_BITS_NUM_13;
  hsdram1.Init.MemoryDataWidth = FMC_SDRAM_MEM_BUS_WIDTH_16;
  hsdram1.Init.InternalBankNumber = FMC_SDRAM_INTERN_BANKS_NUM_4;
  hsdram1.Init.CASLatency = FMC_SDRAM_CAS_LATENCY_2;
  hsdram1.Init.WriteProtection = FMC_SDRAM_WRITE_PROTECTION_DISABLE;
  hsdram1.Init.SDClockPeriod = FMC_SDRAM_CLOCK_PERIOD_3;
  hsdram1.Init.ReadBurst = FMC_SDRAM_RBURST_ENABLE;
  hsdram1.Init.ReadPipeDelay = FMC_SDRAM_RPIPE_DELAY_0;
  /* SdramTiming */
  SdramTiming.LoadToActiveDelay = 2;
  SdramTiming.ExitSelfRefreshDelay = 7;
  SdramTiming.SelfRefreshTime = 4;
  SdramTiming.RowCycleDelay = 7;
  SdramTiming.WriteRecoveryTime = 3;
  SdramTiming.RPDelay = 2;
  SdramTiming.RCDDelay = 2;

  if (HAL_SDRAM_Init(&hsdram1, &SdramTiming) != HAL_OK)
  {
    Error_Handler( );
  }

  /* USER CODE BEGIN FMC_Init 2 */
  SDRAM_Initialization_Sequence(&hsdram1);
  /* USER CODE END FMC_Init 2 */
}

static void MX_GPIO_Init(void)
{
  GPIO_InitTypeDef GPIO_InitStruct = {0};

  /* GPIO Ports Clock Enable */
  __HAL_RCC_GPIOE_CLK_ENABLE();
  __HAL_RCC_GPIOI_CLK_ENABLE();
  __HAL_RCC_GPIOC_CLK_ENABLE();
  __HAL_RCC_GPIOF_CLK_ENABLE();
  __HAL_RCC_GPIOH_CLK_ENABLE();
  __HAL_RCC_GPIOA_CLK_ENABLE();
  __HAL_RCC_GPIOB_CLK_ENABLE();
  __HAL_RCC_GPIOG_CLK_ENABLE();
  __HAL_RCC_GPIOD_CLK_ENABLE();

  /*Configure GPIO pin Output Level */
  HAL_GPIO_WritePin(Buzzer_GPIO_Port, Buzzer_Pin, GPIO_PIN_RESET);

  /*Configure GPIO pin Output Level */
  HAL_GPIO_WritePin(GPIOI, TOUCH_RST_Pin|T_MOSI_Pin, GPIO_PIN_RESET);

  /*Configure GPIO pin Output Level */
  HAL_GPIO_WritePin(GPIOB, LED_GR_Pin|LED_RD_Pin, GPIO_PIN_RESET);

  /*Configure GPIO pin Output Level */
  HAL_GPIO_WritePin(T_CLK_GPIO_Port, T_CLK_Pin, GPIO_PIN_RESET);

  /*Configure GPIO pin : Buzzer_Pin */
  GPIO_InitStruct.Pin = Buzzer_Pin;
  GPIO_InitStruct.Mode = GPIO_MODE_OUTPUT_PP;
  GPIO_InitStruct.Pull = GPIO_NOPULL;
  GPIO_InitStruct.Speed = GPIO_SPEED_FREQ_LOW;
  HAL_GPIO_Init(Buzzer_GPIO_Port, &GPIO_InitStruct);

  /*Configure GPIO pin : TOUCH_RST_Pin */
  GPIO_InitStruct.Pin = TOUCH_RST_Pin;
  GPIO_InitStruct.Mode = GPIO_MODE_OUTPUT_PP;
  GPIO_InitStruct.Pull = GPIO_PULLUP;
  GPIO_InitStruct.Speed = GPIO_SPEED_FREQ_LOW;
  HAL_GPIO_Init(TOUCH_RST_GPIO_Port, &GPIO_InitStruct);

  /*Configure GPIO pin : CARD_DETECT_Pin */
  GPIO_InitStruct.Pin = CARD_DETECT_Pin;
  GPIO_InitStruct.Mode = GPIO_MODE_INPUT;
  GPIO_InitStruct.Pull = GPIO_PULLUP;
  HAL_GPIO_Init(CARD_DETECT_GPIO_Port, &GPIO_InitStruct);

  /*Configure GPIO pins : PF6 PF7 */
  GPIO_InitStruct.Pin = GPIO_PIN_6|GPIO_PIN_7;
  GPIO_InitStruct.Mode = GPIO_MODE_AF_PP;
  GPIO_InitStruct.Pull = GPIO_NOPULL;
  GPIO_InitStruct.Speed = GPIO_SPEED_FREQ_VERY_HIGH;
  GPIO_InitStruct.Alternate = GPIO_AF9_QUADSPI;
  HAL_GPIO_Init(GPIOF, &GPIO_InitStruct);

  /*Configure GPIO pins : PF8 PF9 */
  GPIO_InitStruct.Pin = GPIO_PIN_8|GPIO_PIN_9;
  GPIO_InitStruct.Mode = GPIO_MODE_AF_PP;
  GPIO_InitStruct.Pull = GPIO_NOPULL;
  GPIO_InitStruct.Speed = GPIO_SPEED_FREQ_VERY_HIGH;
  GPIO_InitStruct.Alternate = GPIO_AF10_QUADSPI;
  HAL_GPIO_Init(GPIOF, &GPIO_InitStruct);

  /*Configure GPIO pin : KEY2_Pin */
  GPIO_InitStruct.Pin = KEY2_Pin;
  GPIO_InitStruct.Mode = GPIO_MODE_INPUT;
  GPIO_InitStruct.Pull = GPIO_PULLUP;
  HAL_GPIO_Init(KEY2_GPIO_Port, &GPIO_InitStruct);

  /*Configure GPIO pins : LED_GR_Pin LED_RD_Pin */
  GPIO_InitStruct.Pin = LED_GR_Pin|LED_RD_Pin;
  GPIO_InitStruct.Mode = GPIO_MODE_OUTPUT_PP;
  GPIO_InitStruct.Pull = GPIO_NOPULL;
  GPIO_InitStruct.Speed = GPIO_SPEED_FREQ_LOW;
  HAL_GPIO_Init(GPIOB, &GPIO_InitStruct);

  /*Configure GPIO pin : PB2 */
  GPIO_InitStruct.Pin = GPIO_PIN_2;
  GPIO_InitStruct.Mode = GPIO_MODE_AF_PP;
  GPIO_InitStruct.Pull = GPIO_NOPULL;
  GPIO_InitStruct.Speed = GPIO_SPEED_FREQ_VERY_HIGH;
  GPIO_InitStruct.Alternate = GPIO_AF9_QUADSPI;
  HAL_GPIO_Init(GPIOB, &GPIO_InitStruct);

  /*Configure GPIO pin : T_CLK_Pin */
  GPIO_InitStruct.Pin = T_CLK_Pin;
  GPIO_InitStruct.Mode = GPIO_MODE_OUTPUT_PP;
  GPIO_InitStruct.Pull = GPIO_NOPULL;
  GPIO_InitStruct.Speed = GPIO_SPEED_FREQ_VERY_HIGH;
  HAL_GPIO_Init(T_CLK_GPIO_Port, &GPIO_InitStruct);

  /*Configure GPIO pin : TOUCH_INT_Pin */
  GPIO_InitStruct.Pin = TOUCH_INT_Pin;
  GPIO_InitStruct.Mode = GPIO_MODE_IT_RISING;
  GPIO_InitStruct.Pull = GPIO_PULLUP;
  HAL_GPIO_Init(TOUCH_INT_GPIO_Port, &GPIO_InitStruct);

  /*Configure GPIO pin : T_MISO_Pin */
  GPIO_InitStruct.Pin = T_MISO_Pin;
  GPIO_InitStruct.Mode = GPIO_MODE_INPUT;
  GPIO_InitStruct.Pull = GPIO_NOPULL;
  HAL_GPIO_Init(T_MISO_GPIO_Port, &GPIO_InitStruct);

  /*Configure GPIO pin : T_MOSI_Pin */
  GPIO_InitStruct.Pin = T_MOSI_Pin;
  GPIO_InitStruct.Mode = GPIO_MODE_OUTPUT_PP;
  GPIO_InitStruct.Pull = GPIO_NOPULL;
  GPIO_InitStruct.Speed = GPIO_SPEED_FREQ_VERY_HIGH;
  HAL_GPIO_Init(T_MOSI_GPIO_Port, &GPIO_InitStruct);

  /*Configure GPIO pin : PB6 */
  GPIO_InitStruct.Pin = GPIO_PIN_6;
  GPIO_InitStruct.Mode = GPIO_MODE_AF_PP;
  GPIO_InitStruct.Pull = GPIO_NOPULL;
  GPIO_InitStruct.Speed = GPIO_SPEED_FREQ_VERY_HIGH;
  GPIO_InitStruct.Alternate = GPIO_AF10_QUADSPI;
  HAL_GPIO_Init(GPIOB, &GPIO_InitStruct);

  /* EXTI interrupt init*/
  HAL_NVIC_SetPriority(TOUCH_INT_EXTI_IRQn, 5, 0);
  HAL_NVIC_EnableIRQ(TOUCH_INT_EXTI_IRQn);

}

/* USER CODE BEGIN 4 */
/* -------------------------------------------------------------------------- */
/*                 Print the characters to UART (printf)                      */
/* -------------------------------------------------------------------------- */
/**
  * @brief Print the characters to UART (printf).
  * @retval int
  */
#ifdef __GNUC__
  /* With GCC, small printf (option LD Linker->Libraries->Small printf
     set to 'Yes') calls __io_putchar() */
int __io_putchar(int ch)
#else
int fputc(int ch, FILE *f)
#endif /* __GNUC__ */
{
  /* Place your implementation of fputc here */
  /* e.g. write a character to the UART3 and Loop until the end of transmission */
  HAL_UART_Transmit(&huart2, (uint8_t *)&ch, 1, HAL_MAX_DELAY);
//  HAL_UART_Transmit(&huart2, (uint8_t *)&ch, 1, HAL_MAX_DELAY);
  return ch;
}

void Shutdown()
{
	saveBatteryPercentage();
	PreSleepProcessing(0);
}
volatile uint32_t userButtonPressed = 0;
void HAL_GPIO_EXTI_Callback(uint16_t GPIO_Pin)
{
    if (GPIO_Pin == GPIO_PIN_3)
    {
    	userButtonPressed = 1;
    }

//    if (GPIO_Pin == GPIO_PIN_4)
//    {
//    	polarity = 1;
//    }
//    else
//    {
//    	polarity = 0;
//    }
}

//void HAL_GPIO_EXTI_Callback2(uint16_t GPIO_Pin)
//{
//    if (GPIO_Pin == GPIO_PIN_4)
//    {
//    	polarity = 0;
//    }
//}

uint32_t getSerialNumber(void)
{
	// آدرس UID برای STM32H743
//	uint32_t *UID_ptr = (uint32_t*) 0x1FF1E800;
//	char uid_str[50];  // رشته نهایی قابل ارسال
//	snprintf(uid_str, sizeof(uid_str), "CHIP_ID: %08lX%08lX%08lX\r\n",
//			UID_ptr[0], UID_ptr[1], UID_ptr[2]);
//
//	// ارسال از طریق UART
//	HAL_UART_Transmit(&huart1, (uint8_t*) uid_str, strlen(uid_str),
//			HAL_MAX_DELAY);

	uint32_t serialNumber = *(uint32_t*)(0x1FF1E800);    /*Get Serial Number from chip*/
//	char uid_str[50];
//	snprintf(uid_str, sizeof(uid_str), "CHIP_ID: %08lX%08lX%08lX\r\n",
//			serialNumber[0], serialNumber[1], serialNumber[2]);
	return serialNumber;
}

uint32_t get_random_number(void) {
  uint32_t random = 0;
  if (HAL_RNG_GenerateRandomNumber(&hrng, &random) != HAL_OK) {
    // در صورت خطا، از روش fallback استفاده کنید
    return HAL_GetTick(); // مثال ساده
  }
  return random;
}
/* USER CODE END 4 */

void StartDefaultTask(void *argument)
{
  /* init code for USB_DEVICE */
  MX_USB_DEVICE_Init();
  /* USER CODE BEGIN 5 */
	TickType_t xLastWakeTime;
	xLastWakeTime = xTaskGetTickCount();

	printf("Software Version:(%d.%d.%d.%d)\r\n", Soft_Version[0], Soft_Version[1], Soft_Version[2], Soft_Version[3]);
	printf("UI Version:(%d.%d.%d.%d)\r\n", UI_Version[0], UI_Version[1], UI_Version[2], UI_Version[3]);
	printf("Board Version:(%d.%d.%d.%d)\r\n", Board_Version[0], Board_Version[1], Board_Version[2], Board_Version[3]);

	BuzzerInit(&Buz, Buzzer_GPIO_Port, Buzzer_Pin);
  /* Infinite loop */
  for(;;)
  {
	  vTaskDelayUntil(&xLastWakeTime, pdMS_TO_TICKS(1));
  }
  /* USER CODE END 5 */
}

void StartTaskBrightnessLCD(void *argument)
{
  /* USER CODE BEGIN StartTaskBrightnessLCD */
//	uint32_t lcdBrightnessValue= 255;
//	uint16_t pwmData[255] = {255};
	HAL_TIM_PWM_Start_DMA(&htim3, TIM_CHANNEL_2, (uint32_t*)Brightness_LCD, 1);
//	HAL_TIM_PWM_Start_DMA(&htim3, TIM_CHANNEL_2, (uint32_t*)lcdBrightnessValue, 1);

  /* Infinite loop */
  for(;;)
  {
	  __HAL_TIM_SET_COMPARE(&htim3, TIM_CHANNEL_2, Brightness_LCD);
//	osMessageQueuePut(brtlcdQueueHandle, &lcdBrightnessValue, 0, 0);
//	if (osMessageQueueGetCount(brtlcdQueueHandle)>0)  //  if there is some msg in the queue
//	{
//		if (osMessageQueueGet(brtlcdQueueHandle, &lcdBrightnessValue, 0, 0)== osOK)
//		{
//			__HAL_TIM_SET_COMPARE(&htim3, TIM_CHANNEL_2, lcdBrightnessValue);
//		}
//	}
    osDelay(1);
  }
  /* USER CODE END StartTaskBrightnessLCD */
}

void StartTaskuSD(void *argument)
{
  /* USER CODE BEGIN StartTaskuSD */
	FileCommand cmd;
	SystemInfo status;

//	SD_init();
	/* Infinite loop */
	for (;;)
	{
        if (osMessageQueueGet(fileCommandQueueHandle, &cmd, NULL, osWaitForever) == osOK) {
            switch (cmd.type) {
                case CMD_ENTER_FOLDER:
                    enterFolder(cmd.name);
                    break;
                case CMD_EXIT_FOLDER:
                    exitFolder();
                    break;
                case CMD_GO_TO_ROOT:
                	goToRoot();
                    break;
                case CMD_NEW_FOLDER:
                	createFolder(cmd.name);
                    break;
                case CMD_DELETE_ITEM:
                	deleteItem(cmd.name);
                    break;
                case CMD_NEW_FILE:
                	createFile(cmd.name);
                    break;
                case CMD_RENAME_ITEM:
                	renameItem(cmd.name, cmd.newName);
                    break;
                case CMD_GET_STORAGE_INFO:
                	getStorageInfo();
                    break;
                case CMD_FORMAT_SD:
                    formatSD_Card();
                    break;
                case CMD_READ_FILE:
                	readFile(cmd.name);
                    break;
                case CMD_WRITE_FILE:
                	break;

            }

            // به‌روزرسانی وضعیت سیستم
//            getCurrentPath(status.path, sizeof(status.path));
//            getStorageInfo(&status.totalKB, &status.usedKB, &status.freeKB);
//            osMessageQueuePut(fileToUiQueue, &status, 0, 0);
        }

		osDelay(1);
	}
  /* USER CODE END StartTaskuSD */
}

void StartTouchTask(void *argument)
{
  /* USER CODE BEGIN StartTouchTask */
#ifdef GT911_ENABLE
	  gt911_Init();
	  GTInfo infor;
//	  fwResolution(1024, 600);
	  gt911_SetResolution(1024, 600);
	  readInfo(&infor);
	  printf("x=%d  y=%d\r\n",infor.xResolution,infor.yResolution);
	  if(gt911_ReadID())
	  printf("device found!! \r\n");
	  gt911_TS_Start();
//	  show_config();
//	    if (Gt911_isConnected()) {
//	        printf("GT911 Connected!\n");
//	        gt911_Init();
//	        gt911_TS_Start();
//	    } else {
//	        printf("GT911 Not Found!\n");
////	        while(1);
//	    }

	  // حساسیت بالا (برای صفحات محافظ دار)
	  gt911_SetTouchSensitivity(5, 40);

	  // حساسیت متوسط (پیش‌فرض)
//	  gt911_SetTouchSensitivity(20, 20);

	  // حساسیت پایین (برای محیط‌های مرطوب)
//	  gt911_SetTouchSensitivity(40, 10);

	  gt911_StartCalibration();
	    CheckTouchSensorHealth();

#endif /*GT911_ENABLE*/
	  /* Infinite loop */
	    while(1) {
#ifdef XPT2046_ENABLE
	        if (osMutexAcquire(touch_mutexHandle, osWaitForever) == osOK) {
	            TP_Scan(0);  // اسکن مختصات
	            osMutexRelease(touch_mutexHandle);
	        }
#endif /*XPT2046_ENABLE*/
//	    	vTaskDelay(pdMS_TO_TICKS(1)); // ۱۰۰ هرتز
	    osDelay(1);
	    }
  /* USER CODE END StartTouchTask */
}

void StartTouchCalibKeyTask(void *argument)
{
  /* USER CODE BEGIN StartTouchCalibKeyTask */
#ifdef XPT2046_ENABLE
	uint32_t pressStartTime = 0;
	const uint32_t LONG_PRESS_TIME = 3000; // 3 ثانیه
#endif /* XPT2046_ENABLE */
	/* Infinite loop */
	while (1)
	{
#ifdef XPT2046_ENABLE
		if (HAL_GPIO_ReadPin(GPIOH, GPIO_PIN_3) == GPIO_PIN_RESET)
		{ // دکمه فشرده شده
			if (pressStartTime == 0)
			{
				pressStartTime = osKernelGetTickCount();
			}
			else
			{
				if (osKernelGetTickCount() - pressStartTime >= LONG_PRESS_TIME)
				{

					HAL_GPIO_TogglePin(LED_GR_GPIO_Port, LED_GR_Pin);

//					hx711_t loadcell_CH1;
//					hx711_init(&loadcell_CH1, HX711_CLK_CH1_GPIO_Port, HX711_CLK_CH1_Pin, HX711_DATA_CH1_GPIO_Port, HX711_DATA_CH1_Pin);
//					vTaskResume(calibrationTaskHandle);
//					vTaskSuspend(Weights_TaskHandle);
//					osMutexAcquire(metricsMutexHandle, osWaitForever);
//					hx711_update_calibration(1);
//					hx711_update_calibration_one(&loadcell_CH1);
//					osMutexRelease(metricsMutexHandle);

//					hx711_update_calibration(2);

//                	if (CalibrationActive != 0)
//                	{
//					vTaskSuspend(TouchTaskHandle);
//                		vTaskSuspend(taskAnalogInputHandle);
					//		vTaskSuspend(calibrationTaskHandle);
//                	}

					TP_Adjust();

//                    // ارسال پیام برای ورود به کالیبراسیون
//                    char msg[] = "Entering Calibration Mode";
//                    xQueueSend(xCalibrationQueue, msg, portMAX_DELAY);
//
//                    // تغییر صفحه به calibrationScreen
//                    requestShowCalibrationScreen(); // تابع رابط TouchGFX
					pressStartTime = 0;
				}
			}
		}
		else
		{
			pressStartTime = 0;
		}
#endif /*XPT2046_ENABLE*/
		vTaskDelay(pdMS_TO_TICKS(10));
//	osDelay(10);
	}
  /* USER CODE END StartTouchCalibKeyTask */
}

 /* MPU Configuration */

void MPU_Config(void)
{
  MPU_Region_InitTypeDef MPU_InitStruct = {0};

  /* Disables the MPU */
  HAL_MPU_Disable();

  /** Initializes and configures the Region and the memory to be protected
  */
  MPU_InitStruct.Enable = MPU_REGION_ENABLE;
  MPU_InitStruct.Number = MPU_REGION_NUMBER0;
  MPU_InitStruct.BaseAddress = 0x24000000;
  MPU_InitStruct.Size = MPU_REGION_SIZE_512KB;
  MPU_InitStruct.SubRegionDisable = 0x0;
  MPU_InitStruct.TypeExtField = MPU_TEX_LEVEL0;
  MPU_InitStruct.AccessPermission = MPU_REGION_FULL_ACCESS;
  MPU_InitStruct.DisableExec = MPU_INSTRUCTION_ACCESS_DISABLE;
  MPU_InitStruct.IsShareable = MPU_ACCESS_NOT_SHAREABLE;
  MPU_InitStruct.IsCacheable = MPU_ACCESS_CACHEABLE;
  MPU_InitStruct.IsBufferable = MPU_ACCESS_BUFFERABLE;

  HAL_MPU_ConfigRegion(&MPU_InitStruct);

  /** Initializes and configures the Region and the memory to be protected
  */
  MPU_InitStruct.Number = MPU_REGION_NUMBER1;
  MPU_InitStruct.BaseAddress = 0xC0000000;
  MPU_InitStruct.Size = MPU_REGION_SIZE_512MB;
  MPU_InitStruct.AccessPermission = MPU_REGION_NO_ACCESS;
  MPU_InitStruct.IsCacheable = MPU_ACCESS_NOT_CACHEABLE;
  MPU_InitStruct.IsBufferable = MPU_ACCESS_NOT_BUFFERABLE;

  HAL_MPU_ConfigRegion(&MPU_InitStruct);

  /** Initializes and configures the Region and the memory to be protected
  */
  MPU_InitStruct.Number = MPU_REGION_NUMBER2;
  MPU_InitStruct.Size = MPU_REGION_SIZE_32MB;
  MPU_InitStruct.AccessPermission = MPU_REGION_FULL_ACCESS;
  MPU_InitStruct.IsCacheable = MPU_ACCESS_CACHEABLE;
  MPU_InitStruct.IsBufferable = MPU_ACCESS_BUFFERABLE;

  HAL_MPU_ConfigRegion(&MPU_InitStruct);

  /** Initializes and configures the Region and the memory to be protected
  */
  MPU_InitStruct.Number = MPU_REGION_NUMBER3;
  MPU_InitStruct.BaseAddress = 0x90000000;
  MPU_InitStruct.Size = MPU_REGION_SIZE_512MB;

  HAL_MPU_ConfigRegion(&MPU_InitStruct);

  /** Initializes and configures the Region and the memory to be protected
  */
  MPU_InitStruct.Number = MPU_REGION_NUMBER4;
  MPU_InitStruct.Size = MPU_REGION_SIZE_32MB;
  MPU_InitStruct.DisableExec = MPU_INSTRUCTION_ACCESS_ENABLE;

  HAL_MPU_ConfigRegion(&MPU_InitStruct);

  /** Initializes and configures the Region and the memory to be protected
  */
  MPU_InitStruct.Number = MPU_REGION_NUMBER5;
  MPU_InitStruct.Size = MPU_REGION_SIZE_1MB;

  HAL_MPU_ConfigRegion(&MPU_InitStruct);

  /** Initializes and configures the Region and the memory to be protected
  */
  MPU_InitStruct.Number = MPU_REGION_NUMBER6;
  MPU_InitStruct.BaseAddress = 0x30000000;
  MPU_InitStruct.Size = MPU_REGION_SIZE_64KB;
  MPU_InitStruct.DisableExec = MPU_INSTRUCTION_ACCESS_DISABLE;
  MPU_InitStruct.IsCacheable = MPU_ACCESS_NOT_CACHEABLE;
  MPU_InitStruct.IsBufferable = MPU_ACCESS_NOT_BUFFERABLE;

  HAL_MPU_ConfigRegion(&MPU_InitStruct);

  /** Initializes and configures the Region and the memory to be protected
  */
  MPU_InitStruct.Number = MPU_REGION_NUMBER7;
  MPU_InitStruct.BaseAddress = 0x38000000;
  MPU_InitStruct.Size = MPU_REGION_SIZE_32KB;

  HAL_MPU_ConfigRegion(&MPU_InitStruct);
  /* Enables the MPU */
  HAL_MPU_Enable(MPU_PRIVILEGED_DEFAULT);

}

void HAL_TIM_PeriodElapsedCallback(TIM_HandleTypeDef *htim)
{
  if (htim->Instance == TIM6)
  {
    HAL_IncTick();
  }
}

void Error_Handler(void)
{
  __disable_irq();
  while (1)
  {
  }
}

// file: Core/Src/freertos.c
/* USER CODE BEGIN Header */
/**
  ******************************************************************************
  * File Name          : freertos.c
  * Description        : Code for freertos applications
  ******************************************************************************
  * @attention
  *
  * Copyright (c) 2022 STMicroelectronics.
  * All rights reserved.
  *
  * This software is licensed under terms that can be found in the LICENSE file
  * in the root directory of this software component.
  * If no LICENSE file comes with this software, it is provided AS-IS.
  *
  ******************************************************************************
  */
/* USER CODE END Header */

#include "FreeRTOS.h"
#include "task.h"
#include "main.h"

/* USER CODE BEGIN Variables */
extern LPTIM_HandleTypeDef hlptim1;
/* USER CODE END Variables */

/* USER CODE BEGIN FunctionPrototypes */
extern portBASE_TYPE IdleTaskHook(void* p);
/* USER CODE END FunctionPrototypes */

/* Hook prototypes */
void vApplicationIdleHook(void);
void vApplicationStackOverflowHook(xTaskHandle xTask, signed char *pcTaskName);
void vApplicationMallocFailedHook(void);

/* USER CODE BEGIN 2 */
void vApplicationIdleHook( void )
{
   /* vApplicationIdleHook() will only be called if configUSE_IDLE_HOOK is set
   to 1 in FreeRTOSConfig.h. It will be called on each iteration of the idle
   task. It is essential that code added to this hook function never attempts
   to block in any way (for example, call xQueueReceive() with a block time
   specified, or call vTaskDelay()). If the application makes use of the
   vTaskDelete() API function (as this demo application does) then it is also
   important that vApplicationIdleHook() is permitted to return to its calling
   function, because it is the responsibility of the idle task to clean up
   memory allocated by the kernel to any task that has since been deleted. */
	vTaskSetApplicationTaskTag(NULL, IdleTaskHook);
}
/* USER CODE END 2 */

/* USER CODE BEGIN 4 */
void vApplicationStackOverflowHook(xTaskHandle xTask, signed char *pcTaskName)
{
   /* Run time stack overflow checking is performed if
   configCHECK_FOR_STACK_OVERFLOW is defined to 1 or 2. This hook function is
   called if a stack overflow is detected. */
}
/* USER CODE END 4 */

/* USER CODE BEGIN 5 */
void vApplicationMallocFailedHook(void)
{
   /* vApplicationMallocFailedHook() will only be called if
   configUSE_MALLOC_FAILED_HOOK is set to 1 in FreeRTOSConfig.h. It is a hook
   function that will get called if a call to pvPortMalloc() fails.
   pvPortMalloc() is called internally by the kernel whenever a task, queue,
   timer or semaphore is created. It is also called by various parts of the
   demo application. If heap_1.c or heap_2.c are used, then the size of the
   heap available to pvPortMalloc() is defined by configTOTAL_HEAP_SIZE in
   FreeRTOSConfig.h, and the xPortGetFreeHeapSize() API function can be used
   to query the size of free heap space that remains (although it does not
   provide information on how the remaining heap might be fragmented). */
}
/* USER CODE END 5 */

/* USER CODE BEGIN PREPOSTSLEEP */
__weak void PreSleepProcessing(uint32_t ulExpectedIdleTime)
{
	/* place for user code */
//		HAL_SuspendTick();
	//	HAL_LPTIM_TimeOut_Start_IT(&hlptim1, 0xFFFF, ulExpectedIdleTime);
		ulExpectedIdleTime = 0;
	//	HAL_PWR_EnterSLEEPMode(PWR_MAINREGULATOR_ON, PWR_SLEEPENTRY_WFI);

	//	__HAL_PWR_CLEAR_FLAG(PWR_FLAG_WU);
	//	HAL_PWR_EnableWakeUpPin(PWR_WAKEUP_PIN1);
	//	HAL_PWR_EnterSTANDBYMode();
	 	PWR->WKUPEPR|=1<<0;		//WKUPEN0=1, PA0 is used for WKUP wakeup
	 	PWR->WKUPEPR&=~(1<<8);	//WKUPP0=0, PA0 high level wake-up (rising edge)
	 	PWR->WKUPEPR&=~(3<<16);	//Clear the original settings of WKUPPUPD
		PWR->WKUPEPR|=2<<16;	//WKUPPUPD=10, PA0 pull down
		PWR->WKUPCR|=0X3F<<0;	//Clear WKUP0~5 wake-up flag
		PWR->CPUCR|=7<<0;		//PDDS_D1/D2/D3=1, allow D1/D2/D3 to enter deep sleep mode (PDDS)
	//	PWR->CPUCR|=PWR_CPUCR_PDDS_D3;
		SCB->SCR|=1<<2;			//Enable SLEEPDEEP bit (SYS->CTRL)
	    __DSB ();
	    __ISB ();
		__WFI ();
}

__weak void PostSleepProcessing(uint32_t ulExpectedIdleTime)
{
	/* place for user code */
	//	HAL_LPTIM_TimeOut_Stop(&hlptim1);
//		HAL_GetTick();
		(void) ulExpectedIdleTime;
}
/* USER CODE END PREPOSTSLEEP */
